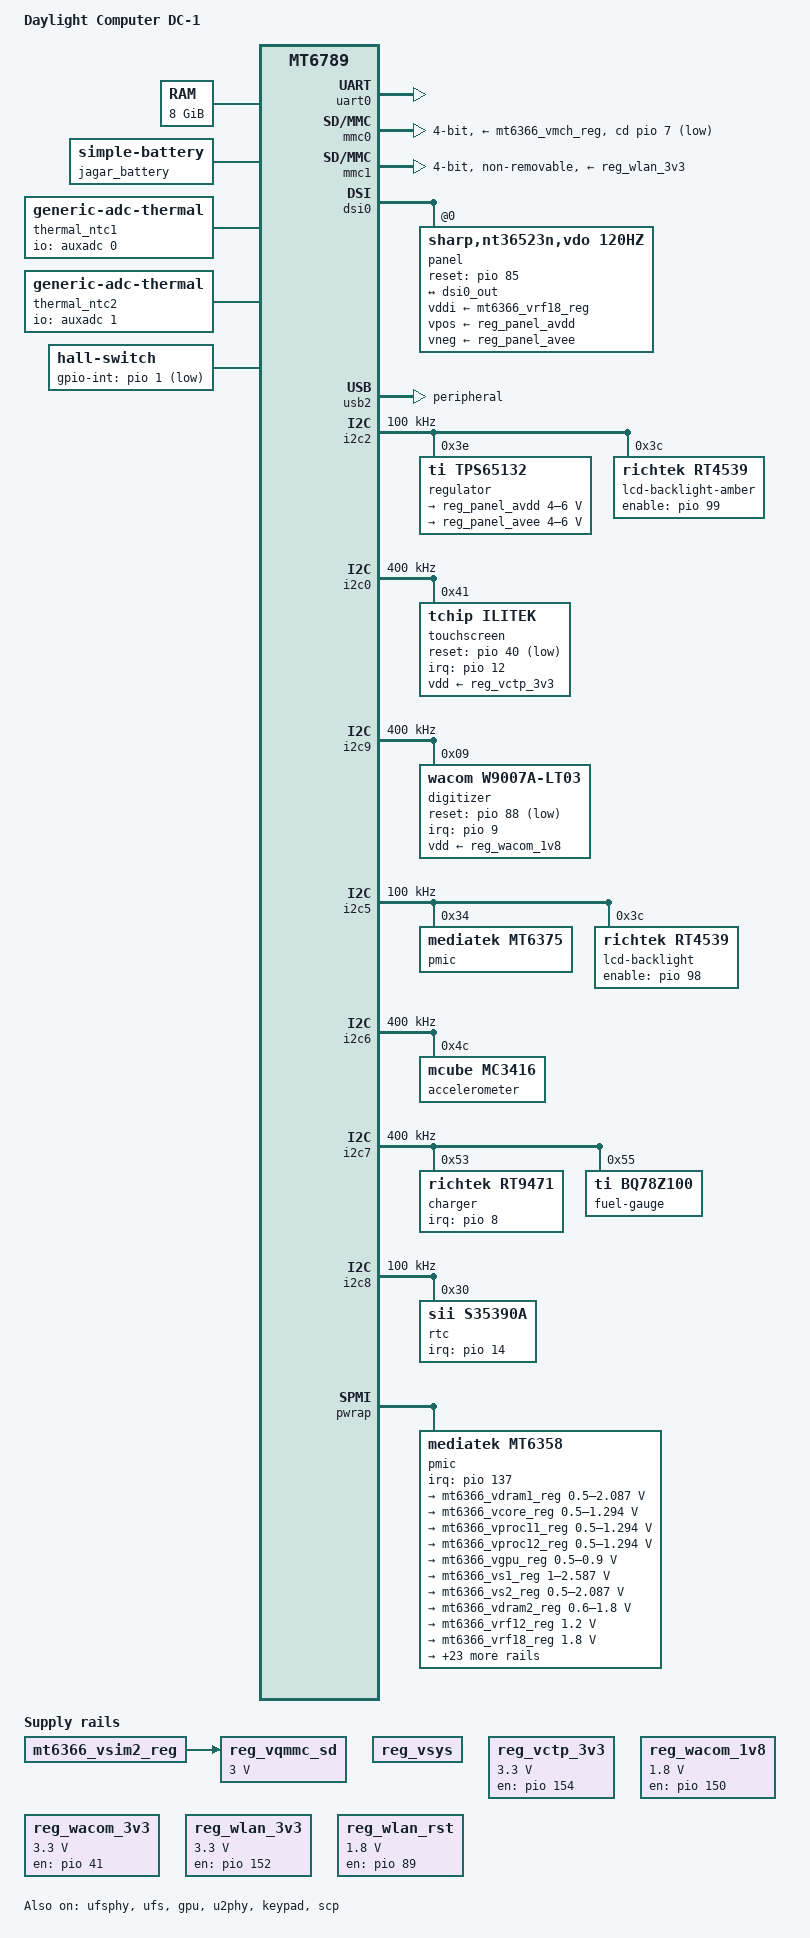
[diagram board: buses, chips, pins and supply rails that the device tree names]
// SPDX-License-Identifier: GPL-2.0
/*
 * Device Tree Source for the Daylight Computer DC-1 tablet ("jagar")
 *
 * SoC:      MediaTek MT8781 (Helio G99) -- register-compatible with MT6789
 * Display:  Sharp NT36523N DSI video-mode panel, 1200x1600 portrait
 * Storage:  UFS (ufshci@11270000) + microSD on MSDC0
 * PMIC:     MT6366 (mt6358 family) over PMIC wrapper
 *
 * Every address, size, GPIO number and pinmux value in this file was read back
 * from the running stock device:
 *   - /sys/firmware/fdt  -> work/live/live.dtb / live.dts   (LK-generated DT)
 *   - /proc/iomem, dmesg, getprop                            (work/live/*.txt)
 * Anything that could NOT be measured is called out in a "XXX UNKNOWN" comment.
 *
 * Layering note: this board file is written against mt6789.dtsi as it exists on
 * linux-mediatek/linux branch mt6789-next (commit 2ed59e4, byte-identical to the
 * copy in work/mainline/tree).  It deliberately does NOT modify the .dtsi; the
 * two SoC-level bugs it has to work around are patched with overrides at the
 * bottom of this file and flagged with "XXX DTSI BUG".
 */

/dts-v1/;

#include <dt-bindings/input/input.h>
#include <dt-bindings/gpio/gpio.h>
#include <dt-bindings/pinctrl/mt65xx.h>
#include <dt-bindings/regulator/mediatek,mt6397-regulator.h>
#include <dt-bindings/pinctrl/mediatek,mt6789-pinfunc.h>

#include "mt6789.dtsi"

/ {
	model = "Daylight Computer DC-1";
	chassis-type = "tablet";
	compatible = "daylight,jagar", "mediatek,mt8781", "mediatek,mt6789";

	#address-cells = <2>;
	#size-cells = <2>;

	aliases {
		mmc0 = &mmc0;
		serial0 = &uart0;
	};

	chosen {
		#address-cells = <2>;
		#size-cells = <2>;
		ranges;

		/*
		 * MTK preloader/LK leave UART0 muxed and running at 921600 8n1.
		 * "earlycon" on the command line resolves through stdout-path and
		 * uses the OF_EARLYCON_DECLARE(mtk8250, "mediatek,mt6577-uart")
		 * hook, so it works before any clock driver has loaded.
		 */
		stdout-path = "serial0:921600n1";

		/*
		 * Fallback command line.  If the boot chain patches /chosen/bootargs
		 * (MTK LK does fdt_setprop on the DT it hands to the kernel) that wins
		 * and this string is discarded, so having it here is strictly safer
		 * than having nothing.
		 *
		 * - earlycon + keep_bootcon: the only console that works before
		 *   clk-mt6789.ko is loaded (uart0's "bus" clock is CLK_IFRAO_UART0,
		 *   whose provider is a module in this defconfig -> mtk8250_probe
		 *   returns -EPROBE_DEFER until then).
		 * - clk/regulator/pd_ignore_unused: stop the kernel gating off the
		 *   clocks, rails and power domains that LK left on for the panel,
		 *   the framebuffer scanout and UFS.
		 * - maxcpus=1: bring up cpu0 only for the first attempt; see the
		 *   CPU discussion at the bottom of this file.
		 * - arm64.nomte mirrors stock; stock has a reason to set it and we
		 *   have no way to know what it is.
		 */
		/*
		 * NO earlycon, and NO console=ttyS0. Both were actively dangerous here.
		 *
		 * earlycon resolves through stdout-path to the 8250 at 0x11002000 and
		 * writes SYNCHRONOUSLY, spinning on the TX FIFO. This board has no UART
		 * header; if the boot chain left UART0's bus clock gated the FIFO never
		 * drains and the kernel hangs before anything reaches pstore -- a
		 * completely silent failure, and the hardest kind to tell apart from
		 * "the kernel never started". It buys us nothing on a headerless device.
		 *
		 * The justification previously given for earlycon -- that clk-mt6789 is
		 * a module so mtk8250_probe returns -EPROBE_DEFER -- is stale:
		 * COMMON_CLK_MT6789 is "default ARCH_MEDIATEK && ARM64"
		 * (drivers/clk/mediatek/Kconfig), so the provider is built in and is
		 * simply omitted from a savedefconfig-style jagar_defconfig.
		 *
		 * console=ttyS0 was LAST, and the last console= becomes /dev/console --
		 * i.e. /dev/console was the headerless UART. console=tty0 is not a
		 * fallback either: DRM_SIMPLEDRM is =y, but it cannot give early
		 * output here -- the simple-framebuffer platform device waits on the
		 * scpsys DISP domain and modular topckgen/mmsys clocks (see the
		 * framebuffer node), so it never probes in time. That is why
		 * arch/arm64/kernel/jagar_fbcon.c exists: it renders printk straight
		 * into LK's scanout and is enabled by 0.002s.
		 *
		 * What actually works with no console= token whatsoever:
		 * pstore_register_console() sets CON_PRINTBUFFER|CON_ENABLED|CON_ANYTIME
		 * with no cmdline opt-in, so ramoops replays the whole log buffer once
		 * pstore_ram probes. That plus the USB gadget (ttyGS0) are the real
		 * channels, and neither needs a console= here.
		 */
		bootargs = "loglevel=8 clk_ignore_unused regulator_ignore_unused pd_ignore_unused nokaslr maxcpus=1 arm64.nomte";

		/*
		 * LK initialises the panel itself and leaves a live scanout in DRAM.
		 * Measured (atag,videolfb-* in the LK-generated DT):
		 *   fb_base_l          = 0xfe8c1000
		 *   vramSize           = 0x1650000   (3 x 0x76c000 + 0xc000 slack)
		 *   islcmfound         = 1
		 *   islcm_inited       = 0   -> the *preloader* did not init the LCM,
		 *                              LK did.  So the panel is only alive
		 *                              because LK left it that way: nothing
		 *                              in this DT may reset the DSI path.
		 * Panel is natively PORTRAIT 1200x1600; the line stride carries 16
		 * pixels of padding, i.e. (1200 + 16) * 4 = 4864 bytes, which is
		 * exactly consistent with vramSize / 3.
		 *
		 * NOTE: deliberately no "power-domains" property here.  Xiaomi
		 * emerald adds power-domains = <&spm MT6789_POWER_DOMAIN_DISP>, which
		 * makes the simple-framebuffer platform device wait for the scpsys
		 * DISP domain -- and that domain needs topckgen/mmsys clocks, which
		 * are modules.  The result is that simpledrm never probes and there is
		 * no display output at all until userspace modprobes.  The domain is
		 * already powered by LK, so we just don't mention it.
		 */
		framebuffer@fe8c1000 {
			compatible = "simple-framebuffer";
			reg = <0x0 0xfe8c1000 0x0 ((1200 + 16) * 1600 * 4)>;
			width = <1200>;
			height = <1600>;
			stride = <((1200 + 16) * 4)>;
			format = "a8r8g8b8";
		};
	};

	/*
	 * 8 GiB in a single contiguous window, two DRAM ranks.
	 * Confirmed twice: the LK DT /memory reg = <0x0 0x40000000 0x2 0x0>, and
	 * the stock emimpu driver printing
	 *   "dram_start(40000000),dram_end(23fffffff)".
	 */
	memory@40000000 {
		device_type = "memory";
		reg = <0x0 0x40000000 0x2 0x00000000>;
	};

	/*
	 * ------------------------------------------------------------------
	 * reserved-memory
	 * ------------------------------------------------------------------
	 * The stock DT declares 26 regions.  A mainline kernel only needs the
	 * ones where *something other than Linux* owns the DRAM, because those
	 * are the ones that either (a) are EMI-MPU protected, so a read/write
	 * from EL1 raises an external abort, or (b) contain live firmware /
	 * a live scanout buffer that we would silently corrupt.
	 *
	 * KEPT and why:
	 *   bl31        TF-A runtime is executing there
	 *   gz, gz_log  GenieZone hypervisor is executing there
	 *   tee_secmem  TEE, EMI-MPU protected
	 *   unmap2      region LK deliberately leaves unmapped
	 *   mcupm       MCUPM firmware is running
	 *   sspm, sspm_ap, debug_met  SSPM firmware is running + its shared/
	 *               profiling buffers (debug_met is contiguous with sspm_ap)
	 *   scp, scp_share  SCP firmware image + AP<->SCP shared buffer
	 *   consys_emi, wifi_dma  connsys (MT7902) EMI windows, MPU protected
	 *   atf_log     TF-A appends to this ring continuously at runtime
	 *   dfdmcu      DFD MCU writes here on reset
	 *   emi_mbist   EMI MBIST scratch
	 *   crypto_hw   1 page, MPU protected
	 *   dramc_rk0/1 the DRAM controller uses the last page of each rank
	 *   framebuffer LK's live scanout buffer, which jagar_fbcon renders the
	 *               early console into -- reserved but deliberately NOT
	 *               no-map (see the comment on that node)
	 *   aee_lk      LK crash buffer; only 8 MiB and it lets LK's AEE survive
	 *   log_store   preloader/LK log ring, readable from LK afterwards
	 *   ramoops     see comment on that node -- this is a *feature* for us
	 *
	 * OMITTED and why:
	 *   ssmr-reserved-cma_memory (0xa000000)  Android "secure memory"
	 *     allocator (mediatek,trusted_mem).  No mainline consumer; it is
	 *     ordinary DRAM that stock steals for DRM/SVP.  Reserving it would
	 *     just cost us 160 MiB of usable RAM.
	 *   aee_debug_kinfo (0x48080000+0x10000)  Android debug_kinfo blob for
	 *     the vendor crash tooling.  Nothing writes it from EL3/EL2.
	 *   minirdump (0x48170000+0x10000)  Android mini ramdump control block.
	 *     Same reasoning.
	 *   No modem regions at all.  Unlike mt6789-motorola-vicky and
	 *     mt8781-zinwa-q25, jagar's stock DT has *no* md_mem/ap_md_smem/
	 *     ccci_tag reservations -- this is a Wi-Fi-only tablet with no
	 *     cellular modem, so there is nothing to reserve.
	 *
	 * RESIDUAL RISK: the stock DT only lists what LK chose to publish.
	 * MT6789 EMI-MPU has 32 regions and jagar's stock kernel logs
	 * "failed to set region permission" during boot, so at least one window
	 * is configured by firmware outside this list.  If the mainline kernel
	 * dies with an unattributed SError early in boot, an undeclared
	 * MPU-protected window is the first thing to suspect.
	 */
	reserved-memory {
		#address-cells = <2>;
		#size-cells = <2>;
		ranges;

		aee_kinfo_reserved: aee-debug-kinfo@48080000 {
			/*
			 * Not strictly needed (see above) but it is 64 KiB and it
			 * sits immediately below ramoops; keeping it means the
			 * 0x48080000..0x48170000 block matches stock exactly.
			 */
			reg = <0x0 0x48080000 0x0 0x10000>;
			no-map;
		};

		/*
		 * Persistent-store console log.
		 *
		 * This is the single most valuable observable-output channel on this
		 * device: it needs no UART, no display and no working USB.  Geometry
		 * is copied *exactly* from the stock kernel command line
		 *   ramoops.mem_address=0x48090000 ramoops.mem_size=0xe0000
		 *   ramoops.record_size=0x40000 ramoops.console_size=0x80000
		 *   ramoops.pmsg_size=0x10000 ramoops.max_reason=5
		 * so that after a failed mainline boot you can reflash boot_a, boot
		 * stock Android (whose pstore uses the same driver and the same
		 * geometry) and read the mainline kernel's console out of
		 * /sys/fs/pstore/console-ramoops-0.
		 *
		 * Requires CONFIG_PSTORE_RAM=y, CONFIG_PSTORE_CONSOLE=y and
		 * CONFIG_PSTORE_PMSG=y (all currently =m/unset).
		 *
		 * We deliberately DO NOT give this node the "ramoops" compatible.
		 * If we did, the ramoops driver would build its zone layout from
		 * the DT properties -- and a DT node has no ftrace-size default
		 * (=> 0), whereas the module-param path LK drives via the kernel
		 * cmdline defaults ftrace to 0x1000. That 0x1000 skew moves the
		 * console zone, so a stock 5.10 kernel (driven by the same LK
		 * cmdline) would read our ring at the wrong offset and report it
		 * empty; it also races the cmdline dummy device for the region.
		 *
		 * Instead this stays a pure no-map reservation so the kernel
		 * cannot allocate over the region, and LK's own cmdline params
		 * (ramoops.mem_address=0x48090000 mem_size=0xe0000
		 * record_size=0x40000 console_size=0x80000 pmsg_size=0x10000
		 * max_reason=5) drive ramoops with EXACTLY the stock layout, so
		 * the ring is byte-compatible for cross-kernel read-back.
		 */
		ramoops_mem: ramoops@48090000 {
			reg = <0x0 0x48090000 0x0 0xe0000>;
			no-map;
		};

		minirdump_mem: minirdump@48170000 {
			reg = <0x0 0x48170000 0x0 0x10000>;
			no-map;
		};

		bl31_mem: bl31@48200000 {
			reg = <0x0 0x48200000 0x0 0x200000>;
			no-map;
		};

		crypto_mem: crypto-hw@48401000 {
			reg = <0x0 0x48401000 0x0 0x1000>;
			no-map;
		};

		/*
		 * LK's crash buffer.  Mapped, not no-map, matching LK's own
		 * mblock-12-aee_lk -- see the framebuffer node for why the
		 * no-map spelling never took effect on any of these four.  A log
		 * buffer the kernel or userspace may want to read back is the
		 * last thing to put outside the linear map.
		 */
		aee_lk_mem: aee-lk@50700000 {
			reg = <0x0 0x50700000 0x0 0x800000>;
		};

		consys_emi_mem: consys-emi@7e000000 {
			reg = <0x0 0x7e000000 0x0 0x500000>;
			no-map;
		};

		tee_sec_mem: tee-secmem@7ea00000 {
			reg = <0x0 0x7ea00000 0x0 0x800000>;
			no-map;
		};

		/*
		 * GenieZone's log ring, matching LK's mblock-6-gz-log.  Mapped
		 * for the same reason as aee-lk above.  Note this is the LOG
		 * region only: gz@7f800000, where the hypervisor is actually
		 * executing, keeps its no-map and must keep it.
		 */
		gz_log_mem: gz-log@7f200000 {
			reg = <0x0 0x7f200000 0x0 0x41000>;
		};

		unmap_mem: unmap@7f400000 {
			reg = <0x0 0x7f400000 0x0 0x400000>;
			no-map;
		};

		gz_mem: gz@7f800000 {
			reg = <0x0 0x7f800000 0x0 0x600000>;
			no-map;
		};

		mcupm_mem: mcupm@7feb0000 {
			reg = <0x0 0x7feb0000 0x0 0x100000>;
			no-map;
		};

		/*
		 * Preloader/LK log ring, matching LK's mblock-7-log_store.
		 * Mapped: tools/logstore-dump.sh exists precisely to read this
		 * back, which no-map would obstruct.
		 */
		log_store_mem: log-store@7ffbf000 {
			reg = <0x0 0x7ffbf000 0x0 0x40000>;
		};

		mbist_mem: emi-mbist@7ffff000 {
			reg = <0x0 0x7ffff000 0x0 0x1000>;
			no-map;
		};

		scp_share_mem: scp-share@8f000000 {
			reg = <0x0 0x8f000000 0x0 0x7a0000>;
			no-map;
		};

		sspm_ap_mem: sspm-ap@9f560000 {
			reg = <0x0 0x9f560000 0x0 0x110000>;
			no-map;
		};

		debug_met_mem: debug-met@9f670000 {
			reg = <0x0 0x9f670000 0x0 0x800000>;
			no-map;
		};

		sspm_mem: sspm@9fe70000 {
			reg = <0x0 0x9fe70000 0x0 0x180000>;
			no-map;
		};

		wifi_mem: wifi@bf000000 {
			reg = <0x0 0xbf000000 0x0 0x600000>;
			no-map;
		};

		scp_mem: scp@bf800000 {
			reg = <0x0 0xbf800000 0x0 0x600000>;
			no-map;
		};

		atf_log_mem: atf-log@bfe00000 {
			reg = <0x0 0xbfe00000 0x0 0x200000>;
			no-map;
		};

		dfdmcu_mem: dfdmcu-dump@fe000000 {
			reg = <0x0 0xfe000000 0x0 0x100000>;
			no-map;
		};

		/*
		 * Live scanout buffer.  Covers the whole stock reservation
		 * (0x173e000), not just the one frame simpledrm maps, because LK's
		 * display engine may still be flipping inside it.
		 *
		 * NO "no-map" here, and that is a deliberate P5.2 reversal of what
		 * this comment used to claim.  The old text said no-map was
		 * "required, not cosmetic" because simpledrm ioremap_wc()s the
		 * range.  Three things refute it:
		 *
		 * 1. It never took effect.  LK PREPENDS its own 25 mblock-N-*
		 *    children into /reserved-memory, so its mblock-13-framebuffer
		 *    -- same reg, no no-map -- is scanned first and takes the
		 *    memblock_reserve().  When this node is reached,
		 *    early_init_dt_reserve_memory() sees the range already
		 *    reserved and returns -EBUSY (of_reserved_mem.c:130), and
		 *    __reserved_mem_reserve_reg() only pr_err()s and carries on
		 *    (:174).  Prepend order verified against the live
		 *    /sys/firmware/fdt: mblock-25 first, mblock-1 last, and the
		 *    one pre-existing vendor child last of all.
		 * 2. It contradicts the console that actually runs.  arch/arm64/
		 *    kernel/jagar_fbcon.c reaches this buffer with __va() from
		 *    setup_arch, and its own header comment states the opposite
		 *    requirement to the old text here: the range must stay in the
		 *    linear map. no-map would make jagar_fbcon_early_init() fatal.
		 * 3. Being mapped costs nothing we need.  LK's reservation already
		 *    keeps the allocator out; "reserved" and "linear-mapped" are
		 *    independent, and mapped is what __va() requires.
		 *
		 * So this is a landmine removed, not a behaviour change: today
		 * both spellings produce an identical mapped range, and only the
		 * no-map spelling breaks the moment LK stops publishing its own
		 * copy.  Pre-registered observable for P5.5: with these four nodes
		 * corrected, the four "Reserved memory: failed to reserve memory
		 * for node" pr_errs should be absent from dmesg.
		 *
		 * If simpledrm is ever made the display path it will need this
		 * range OUT of the linear map, and jagar_fbcon must lose its
		 * __va() in the same commit.  That is a kernel-side decision; do
		 * not make it by editing this node alone.
		 */
		fb_mem: framebuffer@fe8c1000 {
			reg = <0x0 0xfe8c1000 0x0 0x173e000>;
		};

		/*
		 * Last page of each of the two DRAM ranks; the DRAM controller uses
		 * these for calibration/self-refresh scratch.  Stock declares both,
		 * which is independent confirmation of a 2-rank 8 GiB configuration.
		 */
		dramc_rk0_mem: dram-controller@13ffff000 {
			reg = <0x1 0x3ffff000 0x0 0x1000>;
			no-map;
		};

		dramc_rk1_mem: dram-controller@23ffff000 {
			reg = <0x2 0x3ffff000 0x0 0x1000>;
			no-map;
		};
	};

	/* Root of the PMIC supply tree; not a real controllable regulator. */
	reg_vsys: regulator-vsys {
		compatible = "regulator-fixed";
		regulator-name = "vsys";
		regulator-always-on;
		regulator-boot-on;
	};

	/*
	 * Touch and pen rails.  All three are transcribed from the factory
	 * /soc/odm/regulator_* nodes in the merged chain: fixed regulators
	 * gated by a GPIO, enable-active-high, with the exact names and
	 * voltages below.  The GPIO numbers are the factory's, decoded from
	 * <&pio PIN FLAG> triples.
	 */
	reg_vctp_3v3: regulator-vctp-3v3 {
		compatible = "regulator-fixed";
		regulator-name = "VCTP-3V3";
		regulator-min-microvolt = <3300000>;
		regulator-max-microvolt = <3300000>;
		gpio = <&pio 154 GPIO_ACTIVE_HIGH>;
		enable-active-high;
		/*
		 * The ilitek driver does not manage its vdd-supply, so the rail
		 * must already be up when the touchscreen probes; without these
		 * the chip is unpowered and probe fails with -ENXIO.
		 */
		regulator-boot-on;
		regulator-always-on;
	};

	reg_wacom_1v8: regulator-wacom-1v8 {
		compatible = "regulator-fixed";
		regulator-name = "WACOM-1V8";
		regulator-min-microvolt = <1800000>;
		regulator-max-microvolt = <1800000>;
		gpio = <&pio 150 GPIO_ACTIVE_HIGH>;
		enable-active-high;
	};

	/*
	 * The digitiser's second rail.  The factory names it vddl-supply on
	 * the device node, but wacom,w9007a-lt03.yaml is
	 * unevaluatedProperties: false and has no vddl-supply, so it cannot be
	 * referenced from there.  regulator-always-on is what keeps it up
	 * instead; without it nothing would ever enable this rail and the pen
	 * would never answer.  startup-delay-us is the factory's.
	 */
	reg_wacom_3v3: regulator-wacom-3v3 {
		compatible = "regulator-fixed";
		regulator-name = "WACOM-3V3";
		regulator-min-microvolt = <3300000>;
		regulator-max-microvolt = <3300000>;
		gpio = <&pio 41 GPIO_ACTIVE_HIGH>;
		enable-active-high;
		startup-delay-us = <3000>;
		regulator-always-on;
	};

	/*
	 * Battery characteristics.  The factory chain puts this at
	 * /soc/i2c@11f00000/battery -- a child of the i2c7 controller with no
	 * reg, which dtc's own i2c_bus_reg check rejects.  battery.yaml
	 * describes a standalone node that chargers and gauges reach by
	 * phandle, so it moves to the root here and gains a label.
	 *
	 * The three values are read with fdtget from two independent sources:
	 * the reconstructed base+overlay merge and the FDT the boot chain
	 * actually handed a running kernel on this device.  They are mutually
	 * consistent -- 30.8 Wh / 8.0 Ah = 3.85 V nominal exactly, and a 3.4 V
	 * drained figure is 1S -- i.e. one 8000 mAh high-voltage Li-ion cell.
	 *
	 * Two numbers elsewhere in the chain disagree and are NOT used: the
	 * MT6375 charger's cv = 4200 mV, which sits among untouched MediaTek
	 * reference defaults, and the USB-PD bat-info0 design_cap = 3000 mAh,
	 * which carries Richtek's own vid/pid and is a reference-design
	 * placeholder rather than this pack.
	 *
	 * Only the three properties the factory states are declared;
	 * battery.yaml is additionalProperties: false and the rest are not
	 * guessed.  No consumer references this node yet -- see the
	 * monitored-battery note on the fuel gauge.
	 */
	jagar_battery: battery {
		compatible = "simple-battery";
		charge-full-design-microamp-hours = <8000000>;
		energy-full-design-microwatt-hours = <30800000>;
		voltage-min-design-microvolt = <3400000>;
	};

	/*
	 * Single fixed GPU operating point, hardware-proven: the runtime GPU
	 * overlay ran the Mali at exactly 390 MHz / 850 mV on the stock tree
	 * (rails were measured already sitting at 850 mV).  Deliberately not
	 * the dtsi's DVFS table -- no calibrated thermal, no throttling, so no
	 * frequency ladder yet.
	 */
	jagar_gpu_opp: opp-table-gpu-jagar {
		compatible = "operating-points-v2";

		opp-390000000 {
			opp-hz = /bits/ 64 <390000000>;
			opp-microvolt = <850000>;
		};
	};

	/*
	 * microSD card-slot level shifter.  Measured from the stock
	 * /odm/regulator-vqmmc-sdcard node: regulator-gpio on GPIO157,
	 * gpio high = 1.8 V, gpio low = 3.0 V.
	 */
	reg_vqmmc_sd: regulator-vqmmc-sd {
		compatible = "regulator-gpio";
		regulator-name = "sdcard-io";
		regulator-min-microvolt = <3000000>;
		regulator-max-microvolt = <3000000>;
		regulator-settling-time-up-us = <1>;
		regulator-settling-time-down-us = <2>;
		gpios = <&pio 157 GPIO_ACTIVE_HIGH>;
		gpios-states = <0>;
		states = <1800000 0x1>,
			 <3000000 0x0>;
		vin-supply = <&mt6366_vsim2_reg>;
	};

	/*
	 * MT7902 Wi-Fi power, transcribed from the factory dtbo (the signed
	 * overlay LK merges into the stock tree): WLAN-3V3 is a GPIO152-gated
	 * 3.3 V rail (2 ms ramp, 200 ms mandatory off time).  What the factory
	 * tree wires as "vqmmc" is not an IO rail at all but the chip's
	 * reset/power-enable on GPIO89 with a 200 ms settle, dressed as a fixed
	 * 1.8 V regulator so the MMC core sequences it; kept in exactly that
	 * shape here so power-up ordering matches the stock kernel, where this
	 * chip is proven to enumerate (mt7921s bound and scanned on the stock
	 * tree, 2026-08-15).
	 */
	reg_wlan_3v3: regulator-wlan-3v3 {
		compatible = "regulator-fixed";
		regulator-name = "wlan-3v3";
		regulator-min-microvolt = <3300000>;
		regulator-max-microvolt = <3300000>;
		startup-delay-us = <2000>;
		off-on-delay-us = <200000>;
		gpio = <&pio 152 GPIO_ACTIVE_HIGH>;
		enable-active-high;
	};

	reg_wlan_rst: regulator-wlan-rst {
		compatible = "regulator-fixed";
		regulator-name = "wlan-rst";
		pinctrl-names = "default";
		pinctrl-0 = <&wlan_rst_pins>;
		regulator-min-microvolt = <1800000>;
		regulator-max-microvolt = <1800000>;
		startup-delay-us = <200000>;
		gpio = <&pio 89 GPIO_ACTIVE_HIGH>;
		enable-active-high;
	};

	/*
	 * ---------------------------------------------------------------------
	 * Board NTC thermistors
	 * ---------------------------------------------------------------------
	 * The only thermal zones that read on this board today.  Transcribed
	 * from the stock tree, where this exact shape is already bound by our
	 * own kernel: thermal_zone1/2 (ap_ntc, ltepa_ntc) read correctly on the
	 * stock DT right now, via drivers/thermal/thermal-generic-adc.c.
	 *
	 * Both thermistors share one lookup table (they are the same part on
	 * two AUXADC channels); it is copied verbatim from stock, 166 pairs
	 * of <millicelsius adc-raw> descending from 125000 to -40000.
	 */
	thermal_ntc1: thermal-ntc1 {
		compatible = "generic-adc-thermal";
		#thermal-sensor-cells = <0>;
		io-channels = <&auxadc 0>;
		io-channel-names = "sensor-channel";
		temperature-lookup-table = <(-40000) 1760 (-39000) 1757 (-38000) 1754 (-37000) 1751
				             (-36000) 1747 (-35000) 1744 (-34000) 1740 (-33000) 1736
				             (-32000) 1731 (-31000) 1727 (-30000) 1722 (-29000) 1716
				             (-28000) 1711 (-27000) 1705 (-26000) 1699 (-25000) 1693
				             (-24000) 1686 (-23000) 1679 (-22000) 1672 (-21000) 1664
				             (-20000) 1656 (-19000) 1648 (-18000) 1639 (-17000) 1630
				             (-16000) 1620 (-15000) 1610 (-14000) 1599 (-13000) 1588
				             (-12000) 1577 (-11000) 1565 (-10000) 1553 (-9000) 1540
				             (-8000) 1527 (-7000) 1514 (-6000) 1500 (-5000) 1485
				             (-4000) 1470 (-3000) 1455 (-2000) 1439 (-1000) 1423
				             0 1406 1000 1389 2000 1372 3000 1354
				             4000 1335 5000 1317 6000 1298 7000 1279
				             8000 1259 9000 1239 10000 1219 11000 1198
				             12000 1178 13000 1157 14000 1136 15000 1115
				             16000 1093 17000 1072 18000 1050 19000 1029
				             20000 1007 21000 986 22000 964 23000 943
				             24000 921 25000 900 26000 879 27000 858
				             28000 837 29000 816 30000 796 31000 775
				             32000 755 33000 736 34000 716 35000 697
				             36000 678 37000 659 38000 641 39000 623
				             40000 605 41000 588 42000 571 43000 555
				             44000 538 45000 523 46000 507 47000 492
				             48000 477 49000 463 50000 449 51000 435
				             52000 422 53000 409 54000 396 55000 384
				             56000 372 57000 360 58000 349 59000 338
				             60000 327 61000 317 62000 307 63000 297
				             64000 288 65000 279 66000 270 67000 261
				             68000 253 69000 245 70000 237 71000 230
				             72000 222 73000 215 74000 209 75000 202
				             76000 196 77000 189 78000 183 79000 178
				             80000 172 81000 167 82000 161 83000 156
				             84000 151 85000 147 86000 142 87000 138
				             88000 133 89000 129 90000 125 91000 121
				             92000 118 93000 114 94000 111 95000 107
				             96000 104 97000 101 98000 98 99000 95
				             100000 92 101000 89 102000 87 103000 84
				             104000 81 105000 79 106000 77 107000 74
				             108000 72 109000 70 110000 68 111000 66
				             112000 64 113000 62 114000 61 115000 59
				             116000 57 117000 56 118000 54 119000 52
				             120000 51 121000 50 122000 48 123000 47
				             124000 46 125000 44>;
	};

	thermal_ntc2: thermal-ntc2 {
		compatible = "generic-adc-thermal";
		#thermal-sensor-cells = <0>;
		io-channels = <&auxadc 1>;
		io-channel-names = "sensor-channel";
		temperature-lookup-table = <(-40000) 1760 (-39000) 1757 (-38000) 1754 (-37000) 1751
				             (-36000) 1747 (-35000) 1744 (-34000) 1740 (-33000) 1736
				             (-32000) 1731 (-31000) 1727 (-30000) 1722 (-29000) 1716
				             (-28000) 1711 (-27000) 1705 (-26000) 1699 (-25000) 1693
				             (-24000) 1686 (-23000) 1679 (-22000) 1672 (-21000) 1664
				             (-20000) 1656 (-19000) 1648 (-18000) 1639 (-17000) 1630
				             (-16000) 1620 (-15000) 1610 (-14000) 1599 (-13000) 1588
				             (-12000) 1577 (-11000) 1565 (-10000) 1553 (-9000) 1540
				             (-8000) 1527 (-7000) 1514 (-6000) 1500 (-5000) 1485
				             (-4000) 1470 (-3000) 1455 (-2000) 1439 (-1000) 1423
				             0 1406 1000 1389 2000 1372 3000 1354
				             4000 1335 5000 1317 6000 1298 7000 1279
				             8000 1259 9000 1239 10000 1219 11000 1198
				             12000 1178 13000 1157 14000 1136 15000 1115
				             16000 1093 17000 1072 18000 1050 19000 1029
				             20000 1007 21000 986 22000 964 23000 943
				             24000 921 25000 900 26000 879 27000 858
				             28000 837 29000 816 30000 796 31000 775
				             32000 755 33000 736 34000 716 35000 697
				             36000 678 37000 659 38000 641 39000 623
				             40000 605 41000 588 42000 571 43000 555
				             44000 538 45000 523 46000 507 47000 492
				             48000 477 49000 463 50000 449 51000 435
				             52000 422 53000 409 54000 396 55000 384
				             56000 372 57000 360 58000 349 59000 338
				             60000 327 61000 317 62000 307 63000 297
				             64000 288 65000 279 66000 270 67000 261
				             68000 253 69000 245 70000 237 71000 230
				             72000 222 73000 215 74000 209 75000 202
				             76000 196 77000 189 78000 183 79000 178
				             80000 172 81000 167 82000 161 83000 156
				             84000 151 85000 147 86000 142 87000 138
				             88000 133 89000 129 90000 125 91000 121
				             92000 118 93000 114 94000 111 95000 107
				             96000 104 97000 101 98000 98 99000 95
				             100000 92 101000 89 102000 87 103000 84
				             104000 81 105000 79 106000 77 107000 74
				             108000 72 109000 70 110000 68 111000 66
				             112000 64 113000 62 114000 61 115000 59
				             116000 57 117000 56 118000 54 119000 52
				             120000 51 121000 50 122000 48 123000 47
				             124000 46 125000 44>;
	};

	thermal-zones {
		/*
		 * polling-delay 0 on both, matching stock: these are read on
		 * demand and carry no trips, so nothing throttles off them.
		 */
		ap_ntc {
			polling-delay = <0>;
			polling-delay-passive = <0>;
			thermal-sensors = <&thermal_ntc1>;
		};

		ltepa_ntc {
			polling-delay = <0>;
			polling-delay-passive = <0>;
			thermal-sensors = <&thermal_ntc2>;
		};
	};

	/*
	 * ---------------------------------------------------------------------
	 * Hall switch (magnetic lid)
	 * ---------------------------------------------------------------------
	 * Directly AP-wired, one of the board's enabled wakeup sources, and live
	 * today as input2 ("hall-switch") off drivers/input/misc/hall-switch.c.
	 * GPIO 1: the stock overlay's <&pio 1 1> -- the 0xffffffff in the raw
	 * dtbo is the unresolved __fixups__ placeholder for the pio phandle.
	 */
	hall: hall {
		compatible = "hall-switch";
		linux,gpio-int = <&pio 1 1>;
		linux,wakeup;
	};
};

/*
 * ---------------------------------------------------------------------------
 * Console
 * ---------------------------------------------------------------------------
 * No pinctrl-0 on purpose.  The preloader muxes the UART0 pads before we ever
 * run, and we have no measurement telling us *which* pads jagar routes UART0
 * to (mt6789 can put URXD0/UTXD0 on GPIO28/29, 136/137 or 182/183; the stock DT
 * has no pinctrl entry for serial@11002000 either).  Re-muxing a guess could
 * steal a pad that jagar uses for something else, so leave the mux alone.
 *
 * XXX UNKNOWN: whether UART0 is physically accessible on the DC-1 at all
 * (test pads / pogo pins / USB-C sideband).  Nothing in the DT says.
 * Note also that stock boots with mtk_printk_ctrl.disable_uart=1, which is a
 * software gag on the stock kernel only; it does not affect earlycon here.
 */
&uart0 {
	status = "okay";
};

/*
 * ---------------------------------------------------------------------------
 * Storage
 * ---------------------------------------------------------------------------
 */

/*
 * XXX DTSI BUG (mt6789.dtsi:1798, present in both linux-mediatek mt6789-next
 * and ellyq/mtk_g99-mainline): the node is named ufs-phy@11fa0000 but carries
 *   reg = <0 0x01fa0000 0 0xc000>;
 * i.e. the leading "1" of the base address was dropped.  mt8195.dtsi, which
 * this node was cloned from, uses 0x11fa0000, and ufs_mtk_init() unconditionally
 * calls phy_power_on() -> ufs_mtk_phy_set_active(), which does read-modify-write
 * on that mapping.  With the wrong base those accesses land on an address with
 * nothing behind it.
 *
 * Overriding it here rather than editing the .dtsi.  If the device hangs or
 * takes an SError at ufshci probe, the two things to try, in order, are:
 *   1. delete this reg override (go back to the upstream value, which is what
 *      zinwa-q25 reportedly boots with)
 *   2. set status = "disabled" on BOTH &ufsphy and &ufs -- the first boot does
 *      not need UFS at all, the rootfs comes from the boot image ramdisk.
 */
&ufsphy {
	reg = <0 0x11fa0000 0 0xc000>;
	status = "okay";
};

&ufs {
	status = "okay";

	/* Stock: ufshci@11270000 vcc-supply -> mt6366 ldo_vemc. */
	vcc-supply = <&mt6366_vemc_reg>;
};

/*
 * microSD slot.  NOTE the wiring is the opposite way round from every other
 * mt6789 board upstream: because jagar boots from UFS, MSDC0 (which is normally
 * the eMMC controller) is free and the SD slot hangs off it, while MSDC1 carries
 * the MT7902 Wi-Fi SDIO.  On xiaomi-emerald and zinwa-q25 the SD card is on
 * mmc1.  Pins and CD polarity below are the measured stock values.
 */
&mmc0 {
	status = "okay";

	pinctrl-names = "default", "state_uhs";
	pinctrl-0 = <&mmc0_pins_default>;
	/* Factory default and UHS states are electrically identical. */
	pinctrl-1 = <&mmc0_pins_default>;

	bus-width = <4>;
	max-frequency = <25000000>;

	no-mmc;
	no-sdio;
	disable-wp;

	cd-debounce-delay-ms = <0>;
	cd-gpios = <&pio 7 GPIO_ACTIVE_LOW>;

	/*
	 * The factory tree supplies VMMC from the PMIC's VMCH_EINT_HIGH
	 * variant, which gates the rail on the card-detect EINT in hardware.
	 * Mainline has no such regulator and the MT6366 register map for that
	 * sequence is not derivable from any primary source in this repository
	 * or in the vendor tree at /root/vendor-kernel (the vendor DTS names
	 * the node but ships no driver). Until that register map is obtained,
	 * use the plain VMCH LDO and let the MMC core drop the rail on
	 * card removal. Do not reintroduce a guessed EINT register write.
	 */
	vmmc-supply = <&mt6366_vmch_reg>;
	vqmmc-supply = <&reg_vqmmc_sd>;
};

/*
 * MSDC1 = MT7902 Wi-Fi over SDIO (stock cmdline: wlan_mt7902_sdio_mt6789.*).
 * The earlier note here -- "there is no mainline MT7902 driver" -- was wrong:
 * mainline mt7921s drives this chip and did so on this device over the stock
 * tree (wlan0 up, scan returned networks, 2026-08-15).  The stock tree only
 * carries this host because the signed dtbo enables it; a dtbswap boot loses
 * the dtbo, so the board file must describe it itself.  Everything below is
 * transcribed from that dtbo: bus/caps/timing from its fragment@40
 * (mediatek,mt8781-sd), pins from its mmc1@normal / mmc1@uhs states.
 * The host-wake EINT on GPIO21 (vendor mediatek_wifi_ctrl) has no mainline
 * consumer and is not described; DAT1 in-band wakeup covers SDIO IRQs.
 */
&mmc1 {
	status = "okay";

	pinctrl-names = "default", "state_uhs";
	pinctrl-0 = <&mmc1_pins_default>;
	pinctrl-1 = <&mmc1_pins_uhs>;

	bus-width = <4>;
	max-frequency = <200000000>;

	cap-sd-highspeed;
	sd-uhs-sdr25;
	sd-uhs-sdr50;
	sd-uhs-sdr104;

	no-mmc;
	no-sd;
	non-removable;
	cap-sdio-irq;
	keep-power-in-suspend;
	wakeup-source;
	post-power-on-delay-ms = <15>;

	vmmc-supply = <&reg_wlan_3v3>;
	vqmmc-supply = <&reg_wlan_rst>;
};

/*
 * ---------------------------------------------------------------------------
 * Display
 * ---------------------------------------------------------------------------
 * Keep mediatek-drm OUT of the picture.  mt6789.dtsi leaves the whole DDP
 * pipeline (mmsys/mutex/ovl0/rdma0/color0/dither0/dsc0/dsi0) enabled, and
 * CONFIG_DRM_MEDIATEK=m.  If that module ever binds it will reprogram the OVL
 * and RDMA that LK is currently using to scan out our framebuffer, and the
 * screen goes black -- which is exactly the observable output we are trying to
 * get.  Disabling dsi0 leaves DDP_COMPONENT_DSI0 permanently missing from the
 * CRTC path, so mtk_drm's component master never completes and never touches
 * the hardware.  (xiaomi-emerald does the same thing.)
 *
 * The panel itself is a Sharp NT36523N, confirmed three ways:
 *   - stock DSI child node: compatible = "sharp,nt36523n,vdo,120hz"
 *   - stock dmesg loads panel-sharp-nt36523n-vdo-120hz.ko
 *   - packed atag,videolfb string decodes to
 *     "nt36523n_uxga_dsi_vdo_120hz_sharp_lcm_drv"
 * Board wiring, measured:
 *   reset-gpios = <&pio 85 GPIO_ACTIVE_HIGH>
 *   vddi-supply = mt6366 vrf18 (1.8 V)
 *   vpos/vneg   = TPS65132 outp ("LCD_AVDD") / outn ("LCD_AVEE") at i2c2 0x3e,
 *                 enable GPIOs 39 and 38 respectively
 *   TE          = EINT on GPIO83
 *
 * The timings are no longer unknown.  They were recovered from the unstripped
 * vendor module panel-sharp-nt36523n-vdo-120hz.ko together with the init
 * sequence, and both now live in the driver as the
 * "sharp,nt36523n,vdo,120hz" entry of
 * drivers/gpu/drm/panel/panel-novatek-nt36523.c (60 Hz non-DSC mode; the
 * 120 Hz mode needs DSC, which is not wired up).  That is the same compatible
 * the stock DSI child node carries, so the driver already binds this panel on
 * the stock tree -- confirmed on hardware 2026-08-17: with the stock DT,
 * /sys/bus/mipi-dsi/devices/14013000.dsi.0 is bound to panel-novatek-nt36523
 * and DSI-1 reports "connected".
 *
 * Nor does enabling dsi0 still black the screen.  The older warning here was
 * that mtk_drm binding would reprogram the OVL and RDMA that LK is scanning
 * our framebuffer out of.  That is what the staged probe gates now exist to
 * prevent: the panel driver holds at jagar_probe_stage=0 and mtk_cmdq_mailbox
 * at jagar_mt6789_probe_stage=0, and dc1-display-gate raises them (to 3 and 4)
 * only once userspace is ready to be the first DRM master.  The stock tree has
 * dsi0 "okay" and works exactly this way today.
 *
 * So describe the panel.  Board wiring, measured, and cross-checked against
 * the stock panel1@0 node read back from /proc/device-tree:
 *   reset-gpios = <&pio 85 GPIO_ACTIVE_HIGH>   (stock: pin 0x55, flags 0)
 *   vddi-supply = mt6366 vrf18 (1.8 V)
 *   vpos/vneg   = TPS65132 outp ("LCD_AVDD") / outn ("LCD_AVEE") at i2c2 0x3e
 *   TE          = EINT on GPIO83
 * The stock node's remaining properties (islcmfound, sample-id1..3, tps65132ax)
 * are vendor probe hints, not hardware description, and are deliberately not
 * carried over; the driver selects the production init table internally.
 *
 * No "rotation" property, deliberately.  The panel's scanout is 180 degrees
 * from the glass, but the accelerometer's mount-matrix already carries that
 * 180 on top of the chip's physical mounting, exactly as the stock tree leaves
 * it.  Adding rotation = <180> here would make DRM advertise a panel
 * orientation the compositor also compensates for, and the screen would rotate
 * the wrong way round.  If it is ever added, take the 180 back out of the
 * mount-matrix in the same change.
 *
 * XXX Beware: the stock LK DT contains a *stale* scalar property
 *   atag,videolfb-lcmname = "nt36672e_fhdp_dsi_vdo_60hz_jdi_dphy_drv"
 * which contradicts every other source.  It is a leftover default from the
 * reference design; do not trust it.
 */
&dsi0 {
	status = "okay";

	panel@0 {
		compatible = "sharp,nt36523n,vdo,120hz";
		reg = <0>;

		vddi-supply = <&mt6366_vrf18_reg>;
		vpos-supply = <&reg_panel_avdd>;
		vneg-supply = <&reg_panel_avee>;
		reset-gpios = <&pio 85 GPIO_ACTIVE_HIGH>;

		port {
			panel_in: endpoint {
				remote-endpoint = <&dsi0_out>;
			};
		};
	};
};

&dsi0_out {
	remote-endpoint = <&panel_in>;
};

/*
 * Mali-G57 via Panfrost.  The gate that used to keep this disabled -- "wait
 * for the boot-DT transition" -- passed on 2026-08-19: this tree now boots on
 * hardware via dtbswap, and without the node GNOME falls back to llvmpipe.
 * The single OPP and the 850 mV rail level are the values the runtime GPU
 * overlay ran with for days on the stock tree (both rails measured already
 * enabled at 850 mV; the overlay pinned exactly that), NOT the dtsi's DVFS
 * table: calibrated LVTS still does not exist (the driver fail-closes on
 * manual RCK), so there is still no GPU thermal zone, and a fixed
 * known-good operating point is the conservative choice until it does.
 * MFG0/MFG1 domain supplies are set above; MFG2/MFG3 come from the .dtsi.
 */
&gpu {
	mali-supply = <&mt6366_vgpu_reg>;
	operating-points-v2 = <&jagar_gpu_opp>;
	status = "okay";
};

/*
 * ---------------------------------------------------------------------------
 * USB
 * ---------------------------------------------------------------------------
 * MT6789's USB2 block is MUSB ("mediatek,mt6789-musb"/"mediatek,mtk-musb"),
 * confirmed by the stock node usb0@11200000 compatible
 * "mediatek,mt6789-usb20" at the same base with the same IRQ (SPI 128).
 *
 * XXX CONFIG PROBLEM, not a DTS problem: the current .config has
 * CONFIG_USB_MTU3=y but "# CONFIG_USB_MUSB_MEDIATEK is not set".  MTU3 is the
 * *xHCI-style* MediaTek controller and will never match this node, so as
 * configured today enabling usb2 gives no gadget and no USB output channel.
 * CONFIG_USB_MUSB_MEDIATEK must be turned on (=y) for USB to be usable.
 *
 * PHY tuning values below are the measured stock ones and differ from the
 * .dtsi defaults (which say eye-vrt = 4).
 */
&usb2 {
	status = "okay";

	dr_mode = "peripheral";
	maximum-speed = "high-speed";
};

&u2phy {
	status = "okay";
};

&u2port0 {
	/*
	 * Stock usb-phy@11f40000 measured: eye-vrt 7, eye-term 4, discth 7.
	 * eye-term and discth already match the .dtsi; only eye-vrt differs
	 * (the .dtsi says 4), so that is the only value overridden here.
	 *
	 * Two stock properties deliberately NOT carried over:
	 *   mediatek,rx_sqth = 5   -- vendor-only, phy-mtk-tphy has no such
	 *                             property (it understands only bc12,
	 *                             eye-src, eye-vrt, eye-term, intr, discth,
	 *                             pre-emphasis).
	 *   nvmem-cell-names = "intr_cal"  -- mainline spells this cell "intr"
	 *                             and needs an efuse cell node giving its
	 *                             offset/length.  XXX UNKNOWN: that offset.
	 *                             Without it the PHY uses its default
	 *                             (uncalibrated) intr value, which is fine
	 *                             for bring-up but will hurt eye margin.
	 */
	mediatek,eye-vrt = <7>;
};

/*
 * ---------------------------------------------------------------------------
 * I2C buses
 * ---------------------------------------------------------------------------
 * Bus numbering resolved by matching the stock DT register bases against the
 * labels in mt6789.dtsi:
 *   i2c2 @11eb0000  TPS65132 @0x3e (panel AVDD/AVEE), RT4539 amber backlight @0x3c
 *   i2c5 @11017000  RT4539 white backlight @0x3c
 *   i2c7 @11f00000  BQ78Z100 fuel gauge @0x55, RT9471 "secondary_chg" @0x53
 *   i2c8 @11eb2000  Seiko S-35390A RTC @0x30
 *   i2c9 @11eb3000  Wacom EMR digitiser @0x09
 *
 * Also on the shipped chain and now declared below (P5.2): i2c0 @11e00000
 * carries the ilitek touchscreen @0x41, and i2c5 additionally carries the
 * MT6375 PMU @0x34.
 *
 * One bus is NOT on the stock AP chain and is declared below anyway:
 *   i2c6 @1101a000  mCube MC3416 accelerometer @0x4c
 * Stock disables that controller and gives its pins to the SCP; see the
 * comment on &i2c6 for why the AP can have them instead.  The second SCP
 * bus (GPIO132/133, function 1 = SCL1/SDA1 = i2c1 @11e01000) carries an
 * ambient-light/proximity part at 0x49 by the same trick, but no mainline
 * driver claims it, so it stays undeclared.
 *
 * Declared below: the devices that have a driver in this tree and a real
 * binding, including both richtek,rt4539 frontlights -- amber @i2c2 0x3c with
 * enable GPIO99 and white @i2c5 0x3c with enable GPIO98, driven by
 * drivers/video/backlight/rt4539.c (CONFIG_BACKLIGHT_RT4539).
 *
 * P5.2 closed the six-device gap that inventory.py reported between this tree
 * and the merged factory chain.  Three claims that stood in this comment
 * before are RETRACTED, each refuted by re-reading this tree:
 *
 *   emr,wacom_i2c   "no mainline driver" was WRONG.  drivers/input/
 *                   touchscreen/wacom_w9000.c (upstream, "Input: Add support
 *                   for Wacom W9000-series penabled touchscreens") binds
 *                   wacom,w9002 / w9007a-lt03 / w9007a-v1 and has a schema at
 *                   Documentation/devicetree/bindings/input/touchscreen/
 *                   wacom,w9007a-lt03.yaml.  Declared on i2c9 below.
 *   tps65132        the "only consumer would be the panel node we cannot write
 *                   yet" no longer blocks it: the regulators are declared
 *                   standalone with regulator-boot-on, exactly as the factory
 *                   does, and a panel node can adopt them later.
 *   tchip,ilitek    "vendor-only" was WRONG.  It is a jagar-local of_match
 *                   entry added by commit e9cd5ca8ed2d8 to
 *                   drivers/input/touchscreen/ilitek_ts_i2c.c, and :584 keys
 *                   a vendor-reset quirk off exactly that string.  It is NOT
 *                   upstream; an upstream path should identify the part and
 *                   use a real ilitek,ili2xxx compatible.
 *
 * The remaining caveat is schema coverage, not driver coverage: "tchip,ilitek"
 * and "mediatek,mt6375" have drivers but NO binding schema anywhere under
 * Documentation/devicetree/bindings, so both are undocumented-compatible
 * warnings under dtbs_check until schemas are written.  That is the open half
 * of P5.2, tracked in TODO.md.
 *
 * The touchscreen IS described in the shipped chain, but only after the
 * factory DTBO is applied -- the vendor_boot base FDT alone has just an empty
 * /touch node, which is what an earlier base-only read saw.
 */
&i2c2 {
	status = "okay";

	pinctrl-names = "default";
	pinctrl-0 = <&i2c2_pins>;
	clock-frequency = <100000>;

	/*
	 * Panel bias.  outp/outn are the panel's positive and negative rails
	 * (factory regulator-name "LCD_AVDD" / "LCD_AVEE"), each gated by its
	 * own enable GPIO.  drivers/regulator/tps65132-regulator.c binds
	 * "ti,tps65132" and looks the two rails up by the sub-node names
	 * "outp" and "outn"; the factory spells the compatible as a bare
	 * "tps65132" with no vendor prefix, which is exactly the vendor-only
	 * alias P5.2 exists to eliminate.
	 *
	 * The voltage limits are read with fdtget from the merged factory
	 * chain, not from the decompiled text: dtc mis-typed
	 * regulator-min-microvolt as a string and printed it garbled.  Both
	 * rails are 4000000..6000000 uV.
	 *
	 * regulator-boot-on matches the factory: LK has already brought the
	 * panel up, so these must not be treated as off at probe.  No
	 * consumer is wired yet -- a panel node can take them as
	 * power-supply/enable-supply once it exists -- so they are declared
	 * standalone here rather than left out.
	 */
	regulator@3e {
		compatible = "ti,tps65132";
		reg = <0x3e>;

		reg_panel_avdd: outp {
			regulator-name = "LCD_AVDD";
			regulator-min-microvolt = <4000000>;
			regulator-max-microvolt = <6000000>;
			enable-gpios = <&pio 39 GPIO_ACTIVE_HIGH>;
			regulator-boot-on;
		};

		reg_panel_avee: outn {
			regulator-name = "LCD_AVEE";
			regulator-min-microvolt = <4000000>;
			regulator-max-microvolt = <6000000>;
			enable-gpios = <&pio 38 GPIO_ACTIVE_HIGH>;
			regulator-boot-on;
		};
	};

	/*
	 * Amber frontlight.  Every value below is transcribed from the stock
	 * backlight_amber@3c node in the merged factory chain, restricted to
	 * the properties drivers/video/backlight/rt4539.c actually reads; the
	 * vendor-only display/hwcomposer delay properties are deliberately not
	 * carried over.  default-state must be "off": the driver refuses to
	 * probe otherwise, and nothing may light this panel before the display
	 * handoff is accepted.
	 *
	 * The stock enable-GPIO pinctrl state is not carried over either:
	 * mtk-pinctrl muxes a pin to GPIO mode on gpiolib request, so the
	 * enable-gpios reference is sufficient.  If a probe ever finds the pin
	 * left in a peripheral function, that assumption is what to revisit.
	 */
	backlight_amber: backlight@3c {
		/*
		 * Both required by rt4539_read_required_u32(); without them the
		 * driver returns -EINVAL and neither frontlight channel probes.
		 * Values read back from the stock tree, same hardware.
		 */
		screen-off-backlight-off-safety-delay-us = <25000>;
		screen-off-backlight-off-extra-latency-us = <6000>;
		compatible = "richtek,rt4539";
		reg = <0x3c>;

		label = "lcd-backlight-amber";
		default-state = "off";
		enable-gpios = <&pio 99 GPIO_ACTIVE_HIGH>;
		enable-post-delay = <20>;

		max-brightness = <255>;
		max-hw-brightness = <4095>;
		hw-brightness-on-threshold = <16>;

		current = <98>;
		control = <1>;
		time-ctrl = <95>;
		screen-off-backlight-off-time-ctrl = <103>;
		soft-start-ctrl = <2>;
		clk-pfm-ctrl = <121>;
		fbs = <1 1 0 1 0 0>;
	};
};

/*
 * Touchscreen bus.  Unlike i2c2/5/7/8, the factory chain has NO i2c0_default
 * pinctrl state -- it configures no pins for this controller at all -- so
 * i2c0_pins below is NOT transcribed from stock the way the other four are.
 * It is derived from the SoC pin table (SCL0 = GPIO130 func 1, SDA0 = GPIO131
 * func 1, drivers/pinctrl/mediatek/pinctrl-mtk-mt6789.h), which makes it
 * [inferred], not measured.  If touch does not respond, this is the first
 * thing to check against a scope or the bootloader's pin state.
 *
 * The factory runs this bus at 1 MHz (clock-frequency = 0xf4240).  That is
 * Fast-mode Plus and it is not conservative, so it is deliberately dropped to
 * 400 kHz here; raise it only with a working touchscreen to regress against.
 */
&i2c0 {
	status = "okay";

	pinctrl-names = "default";
	pinctrl-0 = <&i2c0_pins>;
	clock-frequency = <400000>;

	/*
	 * Ilitek touchscreen.  "tchip,ilitek" is a jagar-local of_match entry
	 * (added by commit e9cd5ca8ed2d8), not upstream; ilitek_ts_i2c.c:584
	 * keys a vendor-reset quirk off exactly that string, so substituting a
	 * real ilitek,ili2xxx compatible would silently change the reset
	 * sequence this panel expects until that quirk is moved to a proper
	 * device-specific mechanism.
	 *
	 * The driver takes vdd-supply through
	 * devm_regulator_get_enable_optional and the reset line through the
	 * standard "reset-gpios"; the factory's ilitek,irq-gpio and
	 * ilitek,reset-gpio spellings are vendor-only and are dropped in
	 * favour of interrupts and reset-gpios.
	 *
	 * Caveat: no binding schema for "tchip,ilitek" exists anywhere under
	 * Documentation/devicetree/bindings, so this node is an
	 * undocumented-compatible warning under dtbs_check until one is
	 * written.  See the retraction note in the I2C header comment.
	 */
	touchscreen@41 {
		compatible = "tchip,ilitek";
		reg = <0x41>;

		interrupt-parent = <&pio>;
		interrupts = <12 IRQ_TYPE_EDGE_FALLING>;
		/*
		 * RESX is active-low: the driver's assert/deassert sequence must
		 * end with the pin physically high or the controller stays in
		 * reset and NAKs everything (measured: ACTIVE_HIGH left the chip
		 * dead; forcing the pin high brought it up, FW 07 01 00 08).
		 */
		reset-gpios = <&pio 40 GPIO_ACTIVE_LOW>;
		vdd-supply = <&reg_vctp_3v3>;

		pinctrl-names = "default";
		pinctrl-0 = <&ilitek_pins>;
	};
};

/*
 * Wacom EMR digitiser bus.  Same caveat as i2c0: the factory chain has no
 * i2c9_default pinctrl state, so i2c9_pins is [inferred] from the SoC pin
 * table (SCL9 = GPIO148, SDA9 = GPIO149) rather than measured, and the
 * factory 1 MHz rate is dropped to 400 kHz.
 */
&i2c9 {
	status = "okay";

	pinctrl-names = "default";
	pinctrl-0 = <&i2c9_pins>;
	clock-frequency = <400000>;

	/*
	 * The pen digitiser.  The old claim in this file that "emr,wacom_i2c"
	 * has no mainline driver is retracted: drivers/input/touchscreen/
	 * wacom_w9000.c binds wacom,w9002 / wacom,w9007a-lt03 /
	 * wacom,w9007a-v1 with a schema at Documentation/devicetree/bindings/
	 * input/touchscreen/wacom,w9007a-lt03.yaml.
	 *
	 * WHICH of the three variants this panel is has NOT been established.
	 * The factory compatible "emr,wacom_i2c" does not say, and the parts
	 * differ in firmware behaviour rather than in the DT.  w9007a-lt03 is
	 * the starting point because it is the variant the binding is named
	 * for; if the pen enumerates but reports nonsense, try wacom,w9007a-v1
	 * and then wacom,w9002 before suspecting anything else.
	 * [unverified -- no hardware has seen this node]
	 *
	 * The schema is unevaluatedProperties: false and allows vdd-supply but
	 * NOT vddl-supply, so only one of the part's two rails can be named
	 * here.  vdd-supply takes the 1V8 rail, which is what the factory's
	 * vdd-supply points at; the 3V3 rail the factory calls vddl is
	 * declared regulator-always-on instead, since nothing else can turn it
	 * on.  post-power-on-delay-ms = 110 in the factory node likewise has
	 * no schema counterpart and is dropped -- the 3 ms startup delay on
	 * the 3V3 regulator is the only sequencing left.
	 */
	digitizer@9 {
		compatible = "wacom,w9007a-lt03";
		reg = <0x09>;

		interrupt-parent = <&pio>;
		interrupts = <9 IRQ_TYPE_LEVEL_LOW>;
		reset-gpios = <&pio 88 GPIO_ACTIVE_LOW>;
		vdd-supply = <&reg_wacom_1v8>;

		pinctrl-names = "default";
		pinctrl-0 = <&wacom_pins>;
	};
};

/*
 * i2c5 exists only to carry the white frontlight.  The controller is the same
 * part as the amber one at the same address on a different bus, with its own
 * enable GPIO, so both are described identically apart from label and GPIO.
 */
&i2c5 {
	status = "okay";

	pinctrl-names = "default";
	pinctrl-0 = <&i2c5_pins>;
	clock-frequency = <100000>;

	/*
	 * MT6375: one part carrying the primary charger, a Type-C/PD port
	 * controller and an ADC, reached at its PMU bank address 0x34.  The
	 * factory node is a vendor MFD with adc/chg/tcpc/dbg children, an
	 * irq domain of its own and a complete USB-PD description; none of
	 * those five vendor compatibles has a mainline binding or driver, and
	 * MT6375 is not register-compatible with the MT6360/MT6370 parts that
	 * do, so theirs must not be borrowed for it.  [inferred, source
	 * inspection]
	 *
	 * What is described is exactly what drivers/power/supply/
	 * mt6375-charger-readonly.c binds to (of_match_table at :292): a plain
	 * i2c client, no property beyond reg.  That driver reports the charger
	 * configuration the bootloader left behind and cannot change it -- its
	 * regmap .writeable_reg returns false unconditionally.  The Kconfig
	 * symbol is already set in jagar_defconfig but binds nothing today
	 * because no DT node existed, so this node is what finally puts a
	 * charger entry in /sys/class/power_supply/.
	 *
	 * Dropped from the factory node for want of any mainline binding, and
	 * with it: kernel control of charging, USB OTG VBUS, PD negotiation,
	 * role swap and DP alt mode.  The charger keeps running autonomously
	 * on the settings LK left, which is what the read-only driver exists
	 * to observe.  interrupt-controller/interrupts are dropped too: the
	 * driver implements no irq_chip, so publishing an irq domain nothing
	 * drives would only strand a consumer.
	 */
	pmic@34 {
		compatible = "mediatek,mt6375";
		reg = <0x34>;
	};

	backlight_white: backlight@3c {
		/*
		 * Both required by rt4539_read_required_u32(); without them the
		 * driver returns -EINVAL and neither frontlight channel probes.
		 * Values read back from the stock tree, same hardware.
		 */
		screen-off-backlight-off-safety-delay-us = <25000>;
		screen-off-backlight-off-extra-latency-us = <6000>;
		compatible = "richtek,rt4539";
		reg = <0x3c>;

		label = "lcd-backlight";
		default-state = "off";
		enable-gpios = <&pio 98 GPIO_ACTIVE_HIGH>;
		enable-post-delay = <20>;

		max-brightness = <255>;
		max-hw-brightness = <4095>;
		hw-brightness-on-threshold = <16>;

		current = <98>;
		control = <1>;
		time-ctrl = <95>;
		screen-off-backlight-off-time-ctrl = <103>;
		soft-start-ctrl = <2>;
		clk-pfm-ctrl = <121>;
		fbs = <1 1 0 1 0 0>;
	};

	/*
	 * mt6375@34 is also on this bus.  It is not described here: the
	 * compatible the factory uses is vendor-only, and P7.2 owns choosing
	 * how to represent the charger/Type-C/ADC blocks.
	 */
};

/*
 * Sensor bus.  This one is NOT on the factory AP chain at all: stock leaves
 * i2c6 "disabled" and wires GPIO142/143 to function 2 (SCP_SCL1/SCP_SDA1),
 * i.e. the sensor co-processor owns the bus and the sensors are enumerated
 * inside scp_a.img rather than in any device tree.  That is why this tree
 * carried "sensors are unreachable from the AP" for so long.
 *
 * It is wrong.  GPIO142/143 are dual-function: function 1 on the same two
 * pins is SCL6/SDA6, the AP's own i2c6 controller (mt6789 pin table,
 * drivers/pinctrl/mediatek/pinctrl-mtk-mt6789.h).  Re-muxing them to
 * function 1 and scanning finds one device at 0x4c -- the mCube
 * accelerometer -- which answers normally and reports a clean 1.000 g
 * gravity vector.  [measured, 2026-08-16, by bit-banging the two pins
 * through /dev/gpiochip0 before this node existed]
 *
 * Taking the bus away from the SCP is safe here because nothing on this tree
 * drives the SCP: no mainline driver binds "mediatek,mt6789-tinysys-scp", so
 * the node above is declarative only.  The proof is the accelerometer's own
 * state -- it was found in STANDBY (MODE 0x07 = 0), which is its power-on
 * state, so no SCP firmware had ever initialised it.  If an mt6789 sensorhub
 * driver is ever written, it and this node cannot both own these pins.
 *
 * The stock chain configures no i2c6 pinctrl state (the bus is disabled), so
 * the bias here matches what the other buses use rather than being
 * transcribed.  400 kHz is the conservative choice, not a measured one.
 */
&i2c6 {
	status = "okay";

	pinctrl-names = "default";
	pinctrl-0 = <&i2c6_pins>;
	clock-frequency = <400000>;

	/*
	 * mCube MC3416, 7-bit address 0x4c.  Identified by its ID registers
	 * (0x18 = 0xa0, 0x3b = 0x22) and by the shape of its output: the 8-bit
	 * registers the MC3230 uses at 0x00-0x02 are not axis data on this
	 * part, while the 16-bit little-endian pairs at 0x0d/0x0f/0x11 hold a
	 * stationary vector of magnitude 16384 +- 1%, i.e. exactly 1 g at the
	 * part's power-on +-2g range.  drivers/iio/accel/mc3230.c gained a
	 * "mcube,mc3416" entry for the wider samples.
	 *
	 * There is no interrupt line: stock routes the sensor IRQs to the SCP,
	 * not the AP, so the driver polls.  That is enough for orientation.
	 */
	accelerometer@4c {
		compatible = "mcube,mc3416";
		reg = <0x4c>;

		/*
		 * MOUNT-MATRIX-PLACEHOLDER
		 */
		mount-matrix = "1", "0", "0",
			       "0", "1", "0",
			       "0", "0", "1";
	};
};

&i2c7 {
	status = "okay";

	pinctrl-names = "default";
	pinctrl-0 = <&i2c7_pins>;
	clock-frequency = <400000>;

	/*
	 * Secondary charger of jagar's dual-charger topology; the factory
	 * calls it "secondary_chg" and the MT6375 block on i2c5 the primary.
	 * drivers/power/supply/rt9471.c binds this compatible and its schema
	 * richtek,rt9471.yaml is additionalProperties: false, so every vendor
	 * property on the stock node is dropped: chg_alias_name / chg_name are
	 * vendor charger-framework naming, phys/phy-names = "usb2-phy" has no
	 * counterpart because the mainline driver never touches the USB PHY,
	 * and interrupt-controller/#interrupt-cells are unnecessary since the
	 * driver publishes sub-interrupts through its own regmap-irq domain.
	 * Nothing in the shipped chain consumed the stock node's phandle.
	 *
	 * charge-enable-gpios is deliberately NOT set, although the binding
	 * allows it and the pin is known (stock ceb-gpios = <&pio 151
	 * GPIO_ACTIVE_LOW>).  rt9471.c takes that GPIO GPIOD_OUT_HIGH, i.e.
	 * it asserts the active-low CE line at probe and never releases it,
	 * and probe also writes REG_FUNC bit 0 = CHG_EN.  Handing the driver
	 * the GPIO would therefore turn the second charge path ON at first
	 * bind.  Leaving it out makes the pad the only thing holding that
	 * path off, and rt9471_pins parks GPIO151 high -- the level the stock
	 * rt9471_default state programs.  [inferred, source inspection]
	 *
	 * Note when that park happens: a "default" pinctrl state is applied by
	 * pinctrl_bind_pins() immediately before this driver's probe and only
	 * then.  While CONFIG_CHARGER_RT9471 is unset nothing binds, the group
	 * is never applied, and GPIO151 stays as the bootloader left it --
	 * unmeasured here.  Describing the part is inert today; the park is
	 * protection for the boot where the driver is first enabled.  Bringing
	 * up half of a dual-charger topology on a device with a non-removable
	 * battery is still not something to do blind: this node makes the
	 * hardware describable, not enabled.
	 */
	charger@53 {
		compatible = "richtek,rt9471";
		reg = <0x53>;

		interrupts-extended = <&pio 8 IRQ_TYPE_LEVEL_LOW>;
		wakeup-source;

		pinctrl-names = "default";
		pinctrl-0 = <&rt9471_pins>;
	};

	fuel-gauge@55 {
		compatible = "ti,bq78z100";
		reg = <0x55>;

		/*
		 * The battery characteristics are now declared as &jagar_battery
		 * at the root; see the comment there for where the numbers come
		 * from and why they moved out of the bus node.
		 *
		 * monitored-battery is still omitted here, and P5.2 kept that
		 * decision rather than reversing it.  Wiring it up belongs with
		 * P7.1's gauge bring-up, which has to establish the gauge's
		 * supply, reset and seal state first.  Two further reasons found
		 * while checking: battery.yaml itself says a battery node is for
		 * systems with no suitable non-volatile memory or where that NVM
		 * is unprogrammed, and the BQ78Z100 is a smart gauge that has
		 * such flash; and bq27xxx_battery.c calls
		 * power_supply_get_battery_info() before checking di->dm_regs,
		 * which is NULL for this family, so adding the property would
		 * emit a "data memory update not supported" warning on every
		 * boot and change nothing.  Until then the gauge reports
		 * voltage/current/temperature/SoC from its own flash config,
		 * which is enough to be a useful sign of life in
		 * /sys/class/power_supply/.
		 *
		 * bq27xxx.yaml also sets interrupts: false for ti,bq78z100, so
		 * the gauge's alert pin may not be described here.  The factory
		 * node declares none either.
		 */
	};
};

&i2c8 {
	status = "okay";

	pinctrl-names = "default";
	pinctrl-0 = <&i2c8_pins>;
	clock-frequency = <100000>;

	/*
	 * Board RTC, in addition to the PMIC RTC. The factory DTBO configures
	 * GPIO13 and GPIO14 as pulled-up inputs, with GPIO14 alone carrying the
	 * level-low alarm interrupt. Its default-time is intentionally omitted:
	 * retained hardware time or userspace must establish the clock.
	 */
	rtc@30 {
		compatible = "sii,s35390a";
		reg = <0x30>;
		pinctrl-names = "default";
		pinctrl-0 = <&rtc_pins>;
		interrupt-parent = <&pio>;
		interrupts = <14 IRQ_TYPE_LEVEL_LOW>;
		wakeup-source;
	};
};

/*
 * ---------------------------------------------------------------------------
 * PMIC
 * ---------------------------------------------------------------------------
 * MT6366 behind the PMIC wrapper, IRQ on GPIO137, exactly as on the other two
 * mt6789 boards.  Voltage windows are the generic MT6366 ones.
 *
 * Dependency warning: pwrap needs CLK_IFRAO_PMIC_* from infracfg_ao
 * (COMMON_CLK_MT6789=m) and its IRQ from &pio (PINCTRL_MT6789=m), so nothing
 * downstream of this node -- including &ufs's vcc-supply -- can probe until
 * userspace has modprobed those.  That is a config choice, not a DT bug, but it
 * is why the first boot must rely on earlycon + simplefb and not on UFS.
 */
&pwrap {
	status = "okay";

	pmic: pmic {
		compatible = "mediatek,mt6358";
		interrupt-controller;
		interrupts-extended = <&pio 137 IRQ_TYPE_LEVEL_HIGH>;
		#interrupt-cells = <2>;

		mt6366_regulator: mt6366-regulator {
			compatible = "mediatek,mt6366-regulator", "mediatek,mt6358-regulator";

			vsys-ldo1-supply = <&reg_vsys>;
			vsys-ldo2-supply = <&reg_vsys>;
			vsys-ldo3-supply = <&reg_vsys>;
			vsys-vs1-supply = <&reg_vsys>;
			vsys-vs2-supply = <&reg_vsys>;
			vsys-vdram1-supply = <&reg_vsys>;
			vsys-vcore-supply = <&reg_vsys>;
			vsys-vpa-supply = <&reg_vsys>;
			vsys-vproc11-supply = <&reg_vsys>;
			vsys-vproc12-supply = <&reg_vsys>;
			vsys-vgpu-supply = <&reg_vsys>;
			vsys-vmodem-supply = <&reg_vsys>;
			vs1-ldo1-supply = <&mt6366_vs1_reg>;
			vs2-ldo1-supply = <&mt6366_vdram1_reg>;
			vs2-ldo2-supply = <&mt6366_vs2_reg>;
			vs2-ldo3-supply = <&mt6366_vs2_reg>;

			mt6366_vdram1_reg: vdram1 {
				regulator-name = "vdram1";
				regulator-min-microvolt = <500000>;
				regulator-max-microvolt = <2087500>;
				regulator-ramp-delay = <12500>;
				regulator-enable-ramp-delay = <0>;
				regulator-always-on;
				regulator-allowed-modes = <MT6397_BUCK_MODE_AUTO
							   MT6397_BUCK_MODE_FORCE_PWM>;
			};

			mt6366_vcore_reg: vcore {
				regulator-name = "vcore";
				regulator-min-microvolt = <500000>;
				regulator-max-microvolt = <1293750>;
				regulator-ramp-delay = <6250>;
				regulator-enable-ramp-delay = <200>;
				regulator-always-on;
				regulator-allowed-modes = <MT6397_BUCK_MODE_AUTO
							   MT6397_BUCK_MODE_FORCE_PWM>;
			};

			mt6366_vproc11_reg: vproc11 {
				regulator-name = "vproc11";
				regulator-min-microvolt = <500000>;
				regulator-max-microvolt = <1293750>;
				regulator-ramp-delay = <6250>;
				regulator-enable-ramp-delay = <200>;
				regulator-always-on;
				regulator-allowed-modes = <MT6397_BUCK_MODE_AUTO
							   MT6397_BUCK_MODE_FORCE_PWM>;
			};

			mt6366_vproc12_reg: vproc12 {
				regulator-name = "vproc12";
				regulator-min-microvolt = <500000>;
				regulator-max-microvolt = <1293750>;
				regulator-ramp-delay = <6250>;
				regulator-enable-ramp-delay = <200>;
				regulator-always-on;
				regulator-allowed-modes = <MT6397_BUCK_MODE_AUTO
							   MT6397_BUCK_MODE_FORCE_PWM>;
			};

			mt6366_vgpu_reg: vgpu {
				regulator-name = "vgpu";
				regulator-min-microvolt = <500000>;
				regulator-max-microvolt = <900000>;
				regulator-ramp-delay = <6250>;
				regulator-enable-ramp-delay = <200>;
				regulator-allowed-modes = <MT6397_BUCK_MODE_AUTO
							   MT6397_BUCK_MODE_FORCE_PWM>;

				/*
				 * Coupling requires always-on: the regulator core
				 * refuses to couple a rail that can be disabled
				 * ("Coupling of a non always-on regulator is
				 * unimplemented", -ENOTSUPP), which failed the whole
				 * mt6358-regulator probe and with it every supply on
				 * this PMIC.
				 */
				regulator-always-on;
				regulator-coupled-with = <&mt6366_vsram_gpu_reg>;
				regulator-coupled-max-spread = <100000>;
			};

			mt6366_vs1_reg: vs1 {
				regulator-name = "vs1";
				regulator-min-microvolt = <1000000>;
				regulator-max-microvolt = <2587500>;
				regulator-ramp-delay = <12500>;
				regulator-enable-ramp-delay = <0>;
				regulator-always-on;
			};

			mt6366_vs2_reg: vs2 {
				regulator-name = "vs2";
				regulator-min-microvolt = <500000>;
				regulator-max-microvolt = <2087500>;
				regulator-ramp-delay = <12500>;
				regulator-enable-ramp-delay = <0>;
				regulator-always-on;
			};

			/* LPDDR4X, always on */
			mt6366_vdram2_reg: vdram2 {
				regulator-name = "vdram2";
				regulator-min-microvolt = <600000>;
				regulator-max-microvolt = <1800000>;
				regulator-enable-ramp-delay = <3300>;
				regulator-always-on;
			};

			mt6366_vrf12_reg: vrf12 {
				regulator-name = "vrf12";
				regulator-min-microvolt = <1200000>;
				regulator-max-microvolt = <1200000>;
				regulator-enable-ramp-delay = <120>;
				regulator-always-on;
				regulator-boot-on;
			};

			/* Panel VDDI (stock panel1@0 vddi-supply) */
			mt6366_vrf18_reg: vrf18 {
				regulator-name = "vrf18";
				regulator-min-microvolt = <1800000>;
				regulator-max-microvolt = <1800000>;
				regulator-enable-ramp-delay = <120>;
				regulator-always-on;
				regulator-boot-on;
			};

			mt6366_vio18_reg: vio18 {
				regulator-name = "vio18";
				regulator-min-microvolt = <1800000>;
				regulator-max-microvolt = <1800000>;
				regulator-enable-ramp-delay = <2700>;
				regulator-always-on;
				regulator-boot-on;
			};

			mt6366_vio28_reg: vio28 {
				regulator-name = "vio28";
				regulator-min-microvolt = <2800000>;
				regulator-max-microvolt = <2800000>;
				regulator-enable-ramp-delay = <270>;
				regulator-always-on;
				regulator-boot-on;
			};

			mt6366_vusb_reg: vusb {
				regulator-name = "vusb";
				regulator-min-microvolt = <3000000>;
				regulator-max-microvolt = <3100000>;
				regulator-enable-ramp-delay = <270>;
				regulator-always-on;
			};

			mt6366_va12_reg: va12 {
				regulator-name = "va12";
				regulator-min-microvolt = <1200000>;
				regulator-max-microvolt = <1200000>;
				regulator-enable-ramp-delay = <270>;
				regulator-always-on;
			};

			mt6366_vaux18_reg: vaux18 {
				regulator-name = "vaux18";
				regulator-min-microvolt = <1800000>;
				regulator-max-microvolt = <1800000>;
				regulator-enable-ramp-delay = <270>;
				regulator-always-on;
				regulator-boot-on;
			};

			mt6366_vxo22_reg: vxo22 {
				regulator-name = "vxo22";
				regulator-min-microvolt = <2200000>;
				regulator-max-microvolt = <2200000>;
				regulator-enable-ramp-delay = <120>;
				regulator-always-on;
				regulator-boot-on;
			};

			mt6366_vsram_proc11_reg: vsram-proc11 {
				regulator-name = "vsram_proc11";
				regulator-min-microvolt = <500000>;
				regulator-max-microvolt = <1293750>;
				regulator-ramp-delay = <6250>;
				regulator-enable-ramp-delay = <240>;
				regulator-always-on;
			};

			mt6366_vsram_proc12_reg: vsram-proc12 {
				regulator-name = "vsram_proc12";
				regulator-min-microvolt = <500000>;
				regulator-max-microvolt = <1293750>;
				regulator-ramp-delay = <6250>;
				regulator-enable-ramp-delay = <240>;
				regulator-always-on;
			};

			mt6366_vsram_others_reg: vsram-others {
				regulator-name = "vsram_others";
				regulator-min-microvolt = <500000>;
				regulator-max-microvolt = <1293750>;
				regulator-ramp-delay = <6250>;
				regulator-enable-ramp-delay = <240>;
				regulator-always-on;
			};

			mt6366_vsram_core_reg: vsram-core {
				regulator-name = "vsram_core";
				regulator-min-microvolt = <500000>;
				regulator-max-microvolt = <1293750>;
				regulator-enable-ramp-delay = <240>;
				regulator-always-on;
			};

			mt6366_vsram_gpu_reg: vsram-gpu {
				regulator-name = "vsram_gpu";
				regulator-min-microvolt = <750000>;
				regulator-max-microvolt = <950000>;
				regulator-ramp-delay = <6250>;
				regulator-enable-ramp-delay = <240>;

				/*
				 * Coupling requires always-on: the regulator core
				 * refuses to couple a rail that can be disabled
				 * ("Coupling of a non always-on regulator is
				 * unimplemented", -ENOTSUPP), which failed the whole
				 * mt6358-regulator probe and with it every supply on
				 * this PMIC.
				 */
				regulator-always-on;
				regulator-coupled-with = <&mt6366_vgpu_reg>;
				regulator-coupled-max-spread = <100000>;
			};

			/* UFS device VCC (stock ufshci vcc-supply) */
			mt6366_vemc_reg: vemc {
				regulator-name = "vemc";
				regulator-min-microvolt = <2900000>;
				regulator-max-microvolt = <3300000>;
				regulator-enable-ramp-delay = <60>;
				regulator-boot-on;
			};

			/*
			 * microSD VMMC. The factory board tree caps this rail
			 * at 3.0 V (jagar.dts overrides the generic MT6366
			 * 3.3 V maximum), and mainline derives the slot's OCR
			 * mask from these constraints, so keep the same cap.
			 */
			mt6366_vmch_reg: vmch {
				regulator-name = "vmch";
				regulator-min-microvolt = <2900000>;
				regulator-max-microvolt = <3000000>;
				regulator-enable-ramp-delay = <60>;
			};

			/* Fixed input rail for the microSD GPIO level shifter. */
			mt6366_vsim2_reg: vsim2 {
				regulator-name = "vsim2";
				regulator-min-microvolt = <1800000>;
				regulator-max-microvolt = <1800000>;
				regulator-enable-ramp-delay = <60>;
			};

			/*
			 * MSDC1 (Wi-Fi SDIO) pad rail A. The vendor msdc driver
			 * drives this as vioa-supply, a concept mainline mtk-sd
			 * does not have; with it off every MSDC1 pad reads low
			 * (measured 2026-08-19: mux applied, card powered,
			 * MSDC_PS all-zero, CMD5 -ETIMEDOUT) and the MT7902
			 * never enumerates. Always-on is the minimal mainline
			 * shape; the alternative is teaching mtk-sd optional
			 * vioa/viob supplies.
			 */
			mt6366_vcn18_reg: vcn18 {
				regulator-name = "vcn18";
				regulator-min-microvolt = <1800000>;
				regulator-max-microvolt = <1800000>;
				regulator-enable-ramp-delay = <270>;
				regulator-always-on;
			};

			/*
			 * MSDC1 pad rail B (vendor viob-supply), same story as
			 * vcn18 above. The LDO defaults to 3.0 V; the factory
			 * dtbo pins it to exactly 1.8 V for the Wi-Fi pads
			 * (its fragment@38), so mirror that here.
			 */
			mt6366_vmc_reg: vmc {
				regulator-name = "vmc";
				regulator-min-microvolt = <1800000>;
				regulator-max-microvolt = <1800000>;
				regulator-enable-ramp-delay = <60>;
				regulator-always-on;
			};

			mt6366_vcn28_reg: vcn28 {
				regulator-name = "vcn28";
				regulator-min-microvolt = <2800000>;
				regulator-max-microvolt = <2800000>;
				regulator-enable-ramp-delay = <270>;
			};

			mt6366_vcn33_reg: vcn33 {
				regulator-name = "vcn33";
				regulator-min-microvolt = <3300000>;
				regulator-max-microvolt = <3500000>;
				regulator-enable-ramp-delay = <270>;
			};

			mt6366_vaud28_reg: vaud28 {
				regulator-name = "vaud28";
				regulator-min-microvolt = <2800000>;
				regulator-max-microvolt = <2800000>;
				regulator-enable-ramp-delay = <270>;
				regulator-boot-on;
				regulator-always-on;
			};

			mt6366_vibr_reg: vibr {
				regulator-name = "vibr";
				regulator-min-microvolt = <1200000>;
				regulator-max-microvolt = <3300000>;
				regulator-enable-ramp-delay = <60>;
			};

			mt6366_vefuse_reg: vefuse {
				regulator-name = "vefuse";
				regulator-min-microvolt = <1700000>;
				regulator-max-microvolt = <1900000>;
				regulator-enable-ramp-delay = <270>;
			};

			mt6366_vbif28_reg: vbif28 {
				regulator-name = "vbif28";
				regulator-min-microvolt = <2800000>;
				regulator-max-microvolt = <2800000>;
				regulator-enable-ramp-delay = <270>;
			};

			mt6366_vldo28_reg: vldo28 {
				regulator-name = "vldo28";
				regulator-min-microvolt = <2800000>;
				regulator-max-microvolt = <3000000>;
				regulator-enable-ramp-delay = <270>;
				regulator-boot-on;
				regulator-always-on;
			};
		};

		/*
		 * The DC-1 also has a Seiko S-35390A RTC on i2c8 @0x30; the PMIC RTC
		 * is still the one the kernel should use for time keeping.
		 */
		mt6358_rtc: rtc {
			compatible = "mediatek,mt6358-rtc";
		};

		/*
		 * Power and volume-up come in through the PMIC, not through GPIOs:
		 * the stock /odm/gpio-keys node is empty and /mt6366keys carries
		 * KEY_POWER (0x74) and KEY_VOLUMEUP (0x73).
		 * Volume-down is separate: the stock keypad node (mt6779-keypad)
		 * maps matrix (0,0) to KEY_VOLUMEDOWN -- see &keypad below.
		 */
		mt6358_keys: keys {
			compatible = "mediatek,mt6358-keys";

			power-off-time-sec = <0>;
			mediatek,long-press-mode = <1>;

			power {
				linux,keycodes = <KEY_POWER>;
				wakeup-source;
			};

			home {
				linux,keycodes = <KEY_VOLUMEUP>;
			};
		};
	};
};

&pio {
	/*
	 * Measured from the stock pinctrl states mmc0default / mmc0@normal:
	 *   GPIO55 MSDC0_CLK, GPIO56 MSDC0_CMD, GPIO58..61 MSDC0_DAT0..3,
	 *   GPIO7 plain GPIO with pull-up = card detect.
	 * (GPIO57/MSDC0_RSTB is unused -- it only matters for eMMC.)
	 */
	mmc0_pins_default: mmc0-pins-default-state {
		pins-cd {
			pinmux = <PINMUX_GPIO7__FUNC_GPIO7>;
			bias-pull-up;
		};

		pins-clk {
			pinmux = <PINMUX_GPIO55__FUNC_MSDC0_CLK>;
			drive-strength = <3>;
			input-enable;
		};

		pins-cmd-dat {
			pinmux = <PINMUX_GPIO56__FUNC_MSDC0_CMD>,
				 <PINMUX_GPIO58__FUNC_MSDC0_DAT0>,
				 <PINMUX_GPIO59__FUNC_MSDC0_DAT1>,
				 <PINMUX_GPIO60__FUNC_MSDC0_DAT2>,
				 <PINMUX_GPIO61__FUNC_MSDC0_DAT3>;
			drive-strength = <3>;
			input-enable;
		};
	};

	/*
	 * MSDC1 = MT7902 SDIO.  From the factory dtbo mmc1@normal / mmc1@uhs
	 * states: drive level 2 default / 3 UHS, R1R0_01 pull-up on CMD/DAT,
	 * R1R0_10 pull-down on CLK.
	 */
	mmc1_pins_default: mmc1-pins-default-state {
		pins-cmd-dat {
			pinmux = <PINMUX_GPIO72__FUNC_MSDC1_CMD>,
				 <PINMUX_GPIO73__FUNC_MSDC1_DAT0>,
				 <PINMUX_GPIO74__FUNC_MSDC1_DAT1>,
				 <PINMUX_GPIO75__FUNC_MSDC1_DAT2>,
				 <PINMUX_GPIO76__FUNC_MSDC1_DAT3>;
			drive-strength = <2>;
			bias-pull-up = <MTK_PUPD_SET_R1R0_01>;
			input-enable;
		};

		pins-clk {
			pinmux = <PINMUX_GPIO71__FUNC_MSDC1_CLK>;
			drive-strength = <2>;
			bias-pull-down = <MTK_PUPD_SET_R1R0_10>;
		};
	};

	mmc1_pins_uhs: mmc1-pins-uhs-state {
		pins-cmd-dat {
			pinmux = <PINMUX_GPIO72__FUNC_MSDC1_CMD>,
				 <PINMUX_GPIO73__FUNC_MSDC1_DAT0>,
				 <PINMUX_GPIO74__FUNC_MSDC1_DAT1>,
				 <PINMUX_GPIO75__FUNC_MSDC1_DAT2>,
				 <PINMUX_GPIO76__FUNC_MSDC1_DAT3>;
			drive-strength = <3>;
			bias-pull-up = <MTK_PUPD_SET_R1R0_01>;
			input-enable;
		};

		pins-clk {
			pinmux = <PINMUX_GPIO71__FUNC_MSDC1_CLK>;
			drive-strength = <3>;
			bias-pull-down = <MTK_PUPD_SET_R1R0_10>;
		};
	};

	/* WLAN reset line (GPIO89) in plain GPIO mode; the factory dtbo's
	 * pins_reset state, minus its output-low -- the regulator core owns
	 * the level. */
	wlan_rst_pins: wlan-rst-pins {
		pins-rst {
			pinmux = <PINMUX_GPIO89__FUNC_GPIO89>;
		};
	};

	/*
	 * i2c0 and i2c9 bus pins.  These two are NOT measured: the factory
	 * chain has no i2c0_default or i2c9_default state at all, so the pin
	 * numbers come from the SoC pin table in
	 * drivers/pinctrl/mediatek/pinctrl-mtk-mt6789.h (SCL0 = GPIO130,
	 * SDA0 = GPIO131, SCL9 = GPIO148, SDA9 = GPIO149, all function 1) and
	 * the bias matches what the other four buses use.  [inferred]
	 */
	i2c0_pins: i2c0-pins {
		pins-bus {
			pinmux = <PINMUX_GPIO130__FUNC_SCL0>,
				 <PINMUX_GPIO131__FUNC_SDA0>;
			bias-pull-up;
			input-enable;
		};
	};

	i2c9_pins: i2c9-pins {
		pins-bus {
			pinmux = <PINMUX_GPIO148__FUNC_SCL9>,
				 <PINMUX_GPIO149__FUNC_SDA9>;
			bias-pull-up;
			input-enable;
		};
	};

	/*
	 * Touchscreen reset, transcribed from the stock ilitek_default state
	 * (pins_rst: pin 40 func 0, output-low).  The stock active/sleep
	 * states are not carried over: the mainline driver requests only a
	 * "default" state.
	 */
	ilitek_pins: ilitek-pins {
		pins-reset {
			pinmux = <PINMUX_GPIO40__FUNC_GPIO40>;
			output-low;
		};
	};

	/*
	 * Digitiser reset and interrupt, transcribed from the stock
	 * wacom_default state (pins_reset: pin 88 func 0, output-low;
	 * pins_irq: pin 9 func 0, input-enable, bias-disable).  The bias is
	 * deliberately left disabled to match stock -- this line is externally
	 * biased.
	 */
	wacom_pins: wacom-pins {
		pins-reset {
			pinmux = <PINMUX_GPIO88__FUNC_GPIO88>;
			output-low;
		};

		pins-irq {
			pinmux = <PINMUX_GPIO9__FUNC_GPIO9>;
			input-enable;
			bias-disable;
		};
	};

	/*
	 * Secondary-charger CE and INT, transcribed from the stock
	 * rt9471_default state (pins_ceb: pin 151 func 0, output-high;
	 * pins_intr: pin 8 func 0, input-enable, bias-pull-up).  Applied only
	 * when the rt9471 driver binds -- see the note on the charger node.
	 */
	rt9471_pins: rt9471-pins {
		/*
		 * CE is active low and the driver is deliberately not given the
		 * GPIO, so this state alone decides it: high = second charge
		 * path off, which is the level stock programs.
		 */
		pins-ce {
			pinmux = <PINMUX_GPIO151__FUNC_GPIO151>;
			output-high;
		};

		/*
		 * Open-drain active-low INT.  mtk-eint re-muxes this pad to its
		 * EINT mode when the irq is requested; the pull-up and IES here
		 * are the part it does not set.
		 */
		pins-irq {
			pinmux = <PINMUX_GPIO8__FUNC_GPIO8>;
			input-enable;
			bias-pull-up;
		};
	};

	/* All three measured from the stock i2c{2,7,8}_default pinctrl states. */
	i2c2_pins: i2c2-pins {
		pins-bus {
			pinmux = <PINMUX_GPIO134__FUNC_SCL2>,
				 <PINMUX_GPIO135__FUNC_SDA2>;
			bias-pull-up;
			input-enable;
		};
	};

	/* Stock i2c5_default: pins 140/141 in function 1, pulled up. */
	i2c5_pins: i2c5-pins {
		pins-bus {
			pinmux = <PINMUX_GPIO140__FUNC_SCL5>,
				 <PINMUX_GPIO141__FUNC_SDA5>;
			bias-pull-up;
			input-enable;
		};
	};

	i2c7_pins: i2c7-pins {
		pins-bus {
			pinmux = <PINMUX_GPIO144__FUNC_SCL7>,
				 <PINMUX_GPIO145__FUNC_SDA7>;
			bias-pull-up;
		};
	};

	i2c8_pins: i2c8-pins {
		pins-bus {
			pinmux = <PINMUX_GPIO146__FUNC_SCL8>,
				 <PINMUX_GPIO147__FUNC_SDA8>;
			bias-pull-up;
			input-enable;
		};
	};

	/*
	 * The sensor bus.  Not transcribed from stock -- stock muxes these two
	 * pins to function 2 (SCP_SCL1/SCP_SDA1) and disables i2c6 -- but not
	 * inferred either: function 1 on GPIO142/143 is SCL6/SDA6, and the
	 * accelerometer was read over exactly this mux before the node existed.
	 * The bootloader already leaves both pins biased up with input enabled,
	 * which is what is restated here.  [measured]
	 */
	i2c6_pins: i2c6-pins {
		pins-bus {
			pinmux = <PINMUX_GPIO142__FUNC_SCL6>,
				 <PINMUX_GPIO143__FUNC_SDA6>;
			bias-pull-up;
			input-enable;
		};
	};

	rtc_pins: rtc-pins {
		pins-rtc {
			pinmux = <PINMUX_GPIO13__FUNC_GPIO13>,
				 <PINMUX_GPIO14__FUNC_GPIO14>;
			bias-pull-up;
			input-enable;
		};
	};
};

/*
 * Volume-down (and two auxiliary keys) sit on the MediaTek KPD matrix keypad,
 * not on the PMIC.  The stock dtbo already supplies the pinctrl (KPCOL0/1 on
 * GPIO66/67, KPROW0/1 on GPIO68/69) and status=okay via its &keypad fragment;
 * we add the matrix keymap here.  LK applies the stock dtbo on top of this
 * DTB, and its pinctrl encoding matches mainline's (same pinfunc header), so
 * no pinctrl node is re-declared.
 *
 * The stock hw-init-map has three live positions: KEY_VOLUMEDOWN at (0,0),
 * KEY_F11 at (0,1) and KEY_F12 at (1,1); (1,0) is unmapped.  KEY_F11/KEY_F12
 * are transcribed verbatim from stock and need on-device confirmation.
 */
&keypad {
	status = "okay";
	keypad,num-rows = <2>;
	keypad,num-columns = <2>;
	linux,keymap = <
		MATRIX_KEY(0, 0, KEY_VOLUMEDOWN)
		MATRIX_KEY(0, 1, KEY_F11)
		MATRIX_KEY(1, 1, KEY_F12)
	>;
};

/*
 * ---------------------------------------------------------------------------
 * CPUs
 * ---------------------------------------------------------------------------
 * mt6789.dtsi declares and enables all EIGHT cores:
 *   cluster0: cpu0..cpu5  Cortex-A55, MPIDR Aff1 = 0..5 (reg 0x000..0x500)
 *   cluster1: cpu6, cpu7  Cortex-A76, MPIDR Aff1 = 6..7 (reg 0x600, 0x700)
 * (the .dtsi also has the arm,cortex-a76-pmu node commented out, and
 * mt6789-xiaomi-emerald.dts carries a FIXME saying >4 CPUs hangs at boot, that
 * cpu4/cpu5 can be onlined later from sysfs, and that "CPU6 and CPU7 fail to
 * boot due to some capability conflicts")
 *
 * So the two cores that do not work are the two big A76s, cpu6 and cpu7.
 *
 * Recommendation, in order of preference:
 *  1. First boot: do NOT touch the DT, use maxcpus=1 on the command line
 *     (already in the fallback bootargs above).  One core is plenty for
 *     getting output, and it removes secondary bring-up from the list of
 *     things that can hang before we see anything.
 *  2. Once cpu0 boots: uncomment the two overrides below.  Note the property
 *     value MUST be "fail", not "disabled" -- arm64 enumerates CPUs through
 *     of_get_next_cpu_node(), which skips nodes via __of_device_is_fail() only
 *     (drivers/of/base.c:840).  status = "disabled" on a cpu node is silently
 *     ignored and the kernel will still try to PSCI_CPU_ON them.
 *  3. Do not delete the nodes: &cpu6/&cpu7 are referenced by cpu-map,
 *     dsu-pmu, the GIC ppi-partition affinity list and two thermal
 *     cooling-maps.  Marking them "fail" leaves those phandles resolvable;
 *     the affected drivers (arm_dsu_pmu, gic ppi partitions, cpufreq-cooling)
 *     degrade with a warning instead of failing to build the DTB.
 */
/*
&cpu6 {
	status = "fail";
};

&cpu7 {
	status = "fail";
};
*/

/*
 * cpu-supply is deliberately not set on any CPU.  It is only consumed by
 * mediatek-cpufreq, and ARM_MEDIATEK_CPUFREQ_HW is what this SoC uses
 * (performance-domains, already in the .dtsi), which needs no regulator.
 * If classic cpufreq is ever wanted: cpu0..cpu5 -> mt6366_vproc11_reg,
 * cpu6..cpu7 -> mt6366_vproc12_reg (as on emerald).
 */

/*
 * MFG0/MFG1 domain supplies.  These are NOT optional decoration: the MT6789
 * SCPSYS data marks both domains MTK_SCPD_DOMAIN_SUPPLY, and
 * scpsys_add_one_domain() turns a missing "domain-supply" into -ENODEV.
 * scpsys_probe() aborts on the first failing child, so without these two
 * properties mtk-power-controller never calls of_genpd_add_provider_onecell()
 * and *no* MT6789 power domain exists at all -- every consumer of
 * power-domains = <&spm ...> (the whole DISP/SMI/DSI cluster) then defers
 * until the deferred-probe timeout and dies with -ETIMEDOUT.
 *
 * Ownership matches emerald and the jagar GPU probe DT: MFG0 takes vgpu,
 * MFG1 takes vsram_gpu.  Both rails are already regulator-always-on (they
 * are coupled), and both domains are MTK_SCPD_KEEP_DEFAULT_OFF, so this
 * only satisfies the binding; it powers nothing on by itself.
 */
&mfg0 {
	domain-supply = <&mt6366_vgpu_reg>;
};

&mfg1 {
	domain-supply = <&mt6366_vsram_gpu_reg>;
};

/*
 * ---------------------------------------------------------------------------
 * EMI stubs — required by LK, inert to Linux
 * ---------------------------------------------------------------------------
 * LK panics if these are absent from the device tree it is handed. Established
 * by disassembly, not guesswork: emi_info_v2.c looks up "/soc/emicen" (string
 * at lk payload 0x7f7d9, with a bare "/emicen" fallback at 0x7f7dd) and the
 * miss path at 0x16e88 branches to panic() at 0x1732c with
 * "ASSERT FAILED at (%s:%d): %s", line 154; the emimpu and emiisu siblings do
 * the same at lines 38 and 81. fdt_path_offset matches a unit-address suffix,
 * so "/soc/emicen" resolves to emicen@10219000.
 *
 * Mainline has NO driver for mediatek,common-emi* — nothing binds to these and
 * they cost three unused nodes. They exist purely so the bootloader's mandatory
 * fixups find what they expect. Values copied from the stock tree
 * (work/dtmerge/vendor-base.dts:2088-2115), not invented.
 *
 * Reopened by path because mt6789.dtsi's soc node carries no label.
 */
/ {
	soc {
		emicen@10219000 {
			compatible = "mediatek,common-emicen";
			reg = <0 0x10219000 0 0x1000>;
			mediatek,emi-reg = <0x4c>;
		};

		emimpu@10226000 {
			compatible = "mediatek,common-emimpu";
			reg = <0 0x10226000 0 0x1000>;
			mediatek,emi-reg = <0x4d>;
			region_cnt = <0x20>;
			domain_cnt = <0x10>;
		};

		emiisu {
			compatible = "mediatek,common-emiisu";
			ctrl_intf = <1>;
		};
	};
};

/*
 * SCP (sensor co-processor). The firmware is loaded by LK and is already
 * running; this node only maps the SCP's control and tinysys-mailbox
 * registers so the mt6789-scp driver can exchange IPIs with it (the
 * sensorhub path). Layout transcribed from the stock FDT scp@10500000 node.
 */
&scp {
	compatible = "mediatek,mt6789-tinysys-scp";
	status = "okay";

	reg = <0 0x10500000 0 0xc0000>,	/* sram / TCM */
	      <0 0x10724000 0 0x1000>,	/* cfgreg */
	      <0 0x10721000 0 0x1000>,	/* clkreg */
	      <0 0x10730000 0 0x3000>,	/* cfgreg_core0 */
	      <0 0x10740000 0 0x1000>,	/* cfgreg_core1 */
	      <0 0x10752000 0 0x1000>,	/* bus_tracker */
	      <0 0x10760000 0 0x40000>,	/* l1creg */
	      <0 0x107a5000 0 0x4>,		/* cfgreg_sec */
	      <0 0x107fb000 0 0x100>,	/* mbox0_base */
	      <0 0x107fb100 0 0x4>,		/* mbox0_set */
	      <0 0x107fb10c 0 0x4>,		/* mbox0_clr */
	      <0 0x107a5020 0 0x4>,		/* mbox0_init */
	      <0 0x107fc000 0 0x100>,	/* mbox1_base */
	      <0 0x107fc100 0 0x4>,		/* mbox1_set */
	      <0 0x107fc10c 0 0x4>,		/* mbox1_clr */
	      <0 0x107a5024 0 0x4>,		/* mbox1_init */
	      <0 0x107fd000 0 0x100>,	/* mbox2_base */
	      <0 0x107fd100 0 0x4>,		/* mbox2_set */
	      <0 0x107fd10c 0 0x4>,		/* mbox2_clr */
	      <0 0x107a5028 0 0x4>,		/* mbox2_init */
	      <0 0x107fe000 0 0x100>,	/* mbox3_base */
	      <0 0x107fe100 0 0x4>,		/* mbox3_set */
	      <0 0x107fe10c 0 0x4>,		/* mbox3_clr */
	      <0 0x107a502c 0 0x4>,		/* mbox3_init */
	      <0 0x107ff000 0 0x100>,	/* mbox4_base */
	      <0 0x107ff100 0 0x4>,		/* mbox4_set */
	      <0 0x107ff10c 0 0x4>,		/* mbox4_clr */
	      <0 0x107a5030 0 0x4>;		/* mbox4_init */
	reg-names = "scp_sram_base", "scp_cfgreg", "scp_clkreg",
		    "scp_cfgreg_core0", "scp_cfgreg_core1", "scp_bus_tracker",
		    "scp_l1creg", "scp_cfgreg_sec",
		    "mbox0_base", "mbox0_set", "mbox0_clr", "mbox0_init",
		    "mbox1_base", "mbox1_set", "mbox1_clr", "mbox1_init",
		    "mbox2_base", "mbox2_set", "mbox2_clr", "mbox2_init",
		    "mbox3_base", "mbox3_set", "mbox3_clr", "mbox3_init",
		    "mbox4_base", "mbox4_set", "mbox4_clr", "mbox4_init";

	interrupts = <GIC_SPI 466 IRQ_TYPE_LEVEL_HIGH &ppi_cluster0>,
		     <GIC_SPI 467 IRQ_TYPE_LEVEL_HIGH &ppi_cluster0>,
		     <GIC_SPI 468 IRQ_TYPE_LEVEL_HIGH &ppi_cluster0>,
		     <GIC_SPI 469 IRQ_TYPE_LEVEL_HIGH &ppi_cluster0>,
		     <GIC_SPI 470 IRQ_TYPE_LEVEL_HIGH &ppi_cluster0>,
		     <GIC_SPI 471 IRQ_TYPE_LEVEL_HIGH &ppi_cluster0>,
		     <GIC_SPI 472 IRQ_TYPE_LEVEL_HIGH &ppi_cluster0>;
	interrupt-names = "ipc0", "ipc1", "mbox0", "mbox1", "mbox2",
			  "mbox3", "mbox4";

	/* The SCP wake/IPC registers (INFRA_IRQ_SET/CLEAR) live inside the
	 * infracfg_ao syscon block at 0x10001000 (the vendor's
	 * "scp_infra@10001000" is the same silicon). Refer to it as a syscon
	 * so mt6789-scp can poke the SCP awake.
	 */
	mediatek,scp-infra = <&infracfg_ao>;
};

#include "mt8781-daylight-jagar-audio.dtsi"
